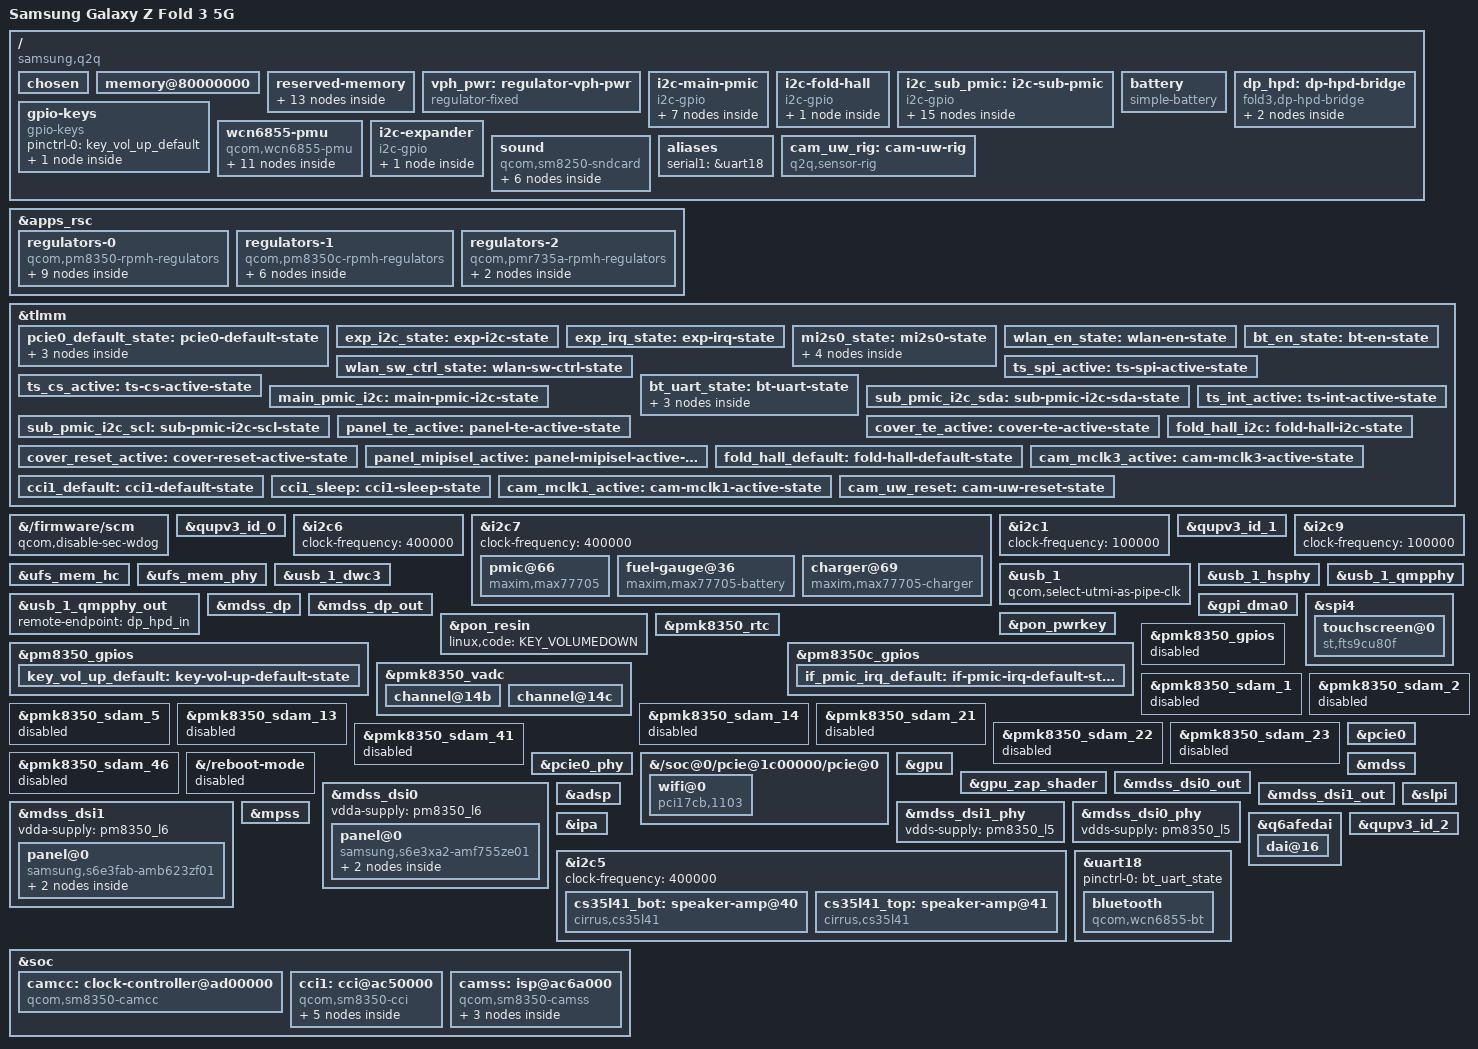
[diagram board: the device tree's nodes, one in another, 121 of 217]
// SPDX-License-Identifier: BSD-3-Clause
/*
 * Samsung Galaxy Z Fold 3 5G (SM-F926B, codename q2q)
 * SoC: Qualcomm SM8350 (lahaina)
 *
 * STAGE 1: deliberately minimal. Boots to an initramfs with a framebuffer
 * console and USB gadget, nothing else. UFS, DSI, Wi-Fi, audio and the
 * remoteprocs all come later -- the point of this file is the smallest thing
 * that can possibly boot, so that a failure has few candidate causes.
 *
 * Modelled on two upstream files:
 *   sm8350-sony-xperia-sagami.dtsi  -- correct SM8350 rails and PMIC labels
 *   sm8450-samsung-r0q.dts          -- Samsung conventions (splash_region, USB 2.0)
 *
 * Board data was read off the device on 2026-11-07, not guessed:
 *   /memory             the four ranges ABL itself publishes (11.90 GiB, 12 GB unit)
 *   reserved-memory     37 regions from the merged post-ABL DT
 *   framebuffer         cont_splash_region + the S6E3XA2 panel timings
 *   ro.revision = 9  ->  board DTS revision r08 is authoritative for this unit
 *
 * NOT BOOTED. NOT TESTED. See dts-work/README.md.
 */

/dts-v1/;

#include <dt-bindings/clock/qcom,sm8350-camcc.h>
#include <dt-bindings/gpio/gpio.h>
#include <dt-bindings/iio/qcom,spmi-adc7-pm8350.h>
#include <dt-bindings/interrupt-controller/arm-gic.h>
#include <dt-bindings/regulator/qcom,rpmh-regulator.h>
#include <dt-bindings/sound/qcom,q6afe.h>
#include <dt-bindings/sound/qcom,q6asm.h>

#include "sm8350.dtsi"
#include "pm8350.dtsi"
#include "pm8350c.dtsi"
#include "pmk8350.dtsi"

/ {
	model = "Samsung Galaxy Z Fold 3 5G";
	compatible = "samsung,q2q", "qcom,sm8350";
	chassis-type = "handset";

	/*
	 * ABL hands us no command line (uniLoader owns it, and the stock one is
	 * console=null anyway), so force our own in the kernel config with
	 * CONFIG_CMDLINE_FORCE.
	 */
	chosen {
		#address-cells = <2>;
		#size-cells = <2>;
		ranges;

		/*
		 * The bootloader framebuffer node is GONE as of the display stack
		 * landing. simpledrm owned it, and simpledrm cannot coexist with
		 * DPU: it would keep scanning out of XBL's surface while DPU
		 * reprograms the display controller under it. See the DISPLAY
		 * section at the end of this file.
		 *
		 * If you need the old console-on-the-bootloader-framebuffer path
		 * back -- e.g. to debug a panel that will not light -- flash
		 * golden/stage4-gpu-*, which still has it.
		 */
	};

	/*
	 * Explicit memory node. uniLoader carries this DT and ABL never rewrites
	 * it, so nothing will fill this in for us.
	 *
	 * These are the exact four ranges ABL publishes to the stock kernel,
	 * read out of the merged post-ABL DT:
	 *   0x080000000 + 0x37500000    893 MiB
	 *   0x0b7b00000 + 0x01e00000     30 MiB
	 *   0x0c0000000 + 0x140000000     5 GiB
	 *   0x200000000 + 0x180000000     6 GiB   = 11.90 GiB total
	 *
	 * Cross-checked: /proc/iomem on the stock kernel reports 11.41 GiB usable
	 * after carve-outs, which is consistent.
	 *
	 * (Worth noting: both the Galaxy S22 port and U-Boot's Qualcomm docs warn
	 * that Samsung bootloaders can emit a bogus or zero-sized memory node.
	 * On this device ABL's memory node is sane. Its *demura_region_0/1*
	 * reserved nodes ARE zero-sized, so the warning is not baseless -- it just
	 * does not apply to /memory here.)
	 */
	memory@80000000 {
		device_type = "memory";
		reg = <0x0 0x80000000 0x0 0x37500000>,
		      <0x0 0xb7b00000 0x0 0x01e00000>,
		      <0x0 0xc0000000 0x1 0x40000000>,
		      <0x2 0x00000000 0x1 0x80000000>;
	};

	reserved-memory {
		/*
		 * Samsung-specific carve-outs that sm8350.dtsi does not know about.
		 * The generic Qualcomm regions (hyp, xbl_aop, smem, cpucp_fw,
		 * cdsp_secure_heap, pil_*, rmtfs, removed, qrtr_shbuf, chan*_shbuf)
		 * are inherited from sm8350.dtsi unchanged -- verified to match
		 * lahaina.dtsi's own values, so upstream is already correct for this
		 * device and must NOT be overridden.
		 */

		/*
		 * Naming here is genuinely ambiguous and worth knowing about.
		 *
		 * Upstream sm8450-samsung-r0q.dts carries the comment "the bootloader
		 * will only keep display hardware enabled if this memory region is
		 * named exactly 'splash_region'" -- and then writes the node as
		 * "splash-region@b8000000", with a hyphen. It contradicts itself.
		 * Samsung's own DT on this device uses "splash_region" (underscore, no
		 * unit address) plus label = "cont_splash_region".
		 *
		 * For OUR boot path it does not matter: uniLoader presents itself to
		 * ABL as a kernel, so ABL never parses this DT at all. The only job
		 * this node has is stopping Linux from allocating over the framebuffer.
		 * We keep the underscore (matching both the stated requirement and
		 * Samsung) and add a unit address so dtc stays quiet.
		 *
		 * If we ever boot WITHOUT uniLoader -- e.g. the Galaxy M52 approach of
		 * injecting a DT into vendor_boot, where ABL does read it -- and the
		 * display dies, try renaming this to bare "splash_region" first.
		 */
		/*
		 * ADSP. NOT inherited from sm8350.dtsi -- the header comment's
		 * "pil_* verified to match" was wrong for this one. The merged
		 * post-ABL DT puts the PIL regions here:
		 *     pil_adsp    0x85200000 + 0x3000000   (upstream: 0x86100000 + 0x2100000)
		 *     pil_camera  0x9b800000, pil_video 0x9bd00000,
		 *     pil_cvp     0x9c200000, pil_slpi  0x9c700000
		 * i.e. Samsung grew the ADSP down over upstream's camera/video/cvp
		 * slots and moved those above the modem. The three upstream slots
		 * are deleted and the ADSP gets the vendor's 48 MiB. Net reserved
		 * memory is unchanged (0x85200000-0x88200000 was all no-map before).
		 *
		 * camera/video/cvp/slpi are NOT re-declared at Samsung's addresses:
		 * nothing loads them, and 0x9bb00000 is where uniLoader relocates
		 * the kernel payloads. Upstream's pil_slpi_mem (0x88200000) stays,
		 * unused.
		 */
		/delete-node/ memory@85200000;
		/delete-node/ memory@85700000;
		/delete-node/ memory@85c00000;
		/delete-node/ memory@86100000;

		pil_adsp_mem: memory@85200000 {
			reg = <0x0 0x85200000 0x0 0x3000000>;
			no-map;
		};

		/*
		 * SLPI (sensor hub: the LSM6DSO IMU and friends live behind it).
		 * slpi.mdt is linked at 0x88200000 and spans exactly 0x1600000
		 * (22 MiB, measured from its program headers). Upstream's slot
		 * at 0x88200000 is 0x1500000 and abuts pil_cdsp at 0x89700000,
		 * so the image cannot fit there -- which is why Samsung moved it.
		 * Use Samsung's own slot from the merged post-ABL DT.
		 *
		 * CONSTRAINT: ABL loads the uniLoader blob at 0x9bb00000 and the
		 * FDT the kernel keeps using stays inside it, just after the
		 * Image (0x9ec9d000 with a 47.5 MiB Image). This no-map region
		 * ends at 0x9dd00000. If the Image ever shrinks below ~34 MiB
		 * the FDT lands inside it and the boot dies very early.
		 */
		/delete-node/ memory@88200000;

		pil_slpi_mem: memory@9c700000 {
			reg = <0x0 0x9c700000 0x0 0x1600000>;
			no-map;
		};

		splash_region: splash_region@e4000000 {
			reg = <0x0 0xe4000000 0x0 0x2300000>;
			label = "cont_splash_region";
			no-map;
		};

		dfps_data_region@e6300000 {
			reg = <0x0 0xe6300000 0x0 0x100000>;
			no-map;
		};

		/*
		 * Samsung TrustZone / "Universal Hypervisor" (RKP). Installed by the
		 * bootloader before any kernel runs, so this memory is occupied no
		 * matter whose kernel boots. Touching it faults.
		 */
		tima_region@b0100000 {
			reg = <0x0 0xb0100000 0x0 0x100000>;
			no-map;
		};

		uh_heap_region@b0200000 {
			reg = <0x0 0xb0200000 0x0 0x200000>;
			no-map;
		};

		uh_guest_region@b0400000 {
			reg = <0x0 0xb0400000 0x0 0x1800000>;
			no-map;
		};

		hdm_region@9fb00000 {
			reg = <0x0 0x9fb00000 0x0 0x1000>;
			no-map;
		};

		/* Where ABL leaves the KASLR seed. */
		kaslr_region@a0001000 {
			reg = <0x0 0xa0001000 0x0 0x1000>;
			no-map;
		};

		/* Samsung debug areas. Reserved so the kernel does not reuse them. */
		sec_debug_region@f0000000 {
			reg = <0x0 0xf0000000 0x0 0x900000>;
			no-map;
		};

		ss_plog_region@f0900000 {
			reg = <0x0 0xf0900000 0x0 0x200000>;
			no-map;
		};

		sec_debug_rdx_bootdev@100000000 {
			reg = <0x1 0x00000000 0x0 0xad00000>;
			no-map;
		};

		/*
		 * ramoops. With no UART, this is the only way to read a panic from
		 * the *previous* boot, so it is worth having from day one.
		 * Deliberately NOT no-map: pstore has to be able to map it.
		 */
		ramoops_region: ramoops@f0b00000 {
			compatible = "ramoops";
			reg = <0x0 0xf0b00000 0x0 0x100000>;
			/*
			 * Mirrors Samsung's own ramoops node byte for byte: four
			 * 256 KiB zones filling the 1 MiB region, and NO ecc-size.
			 *
			 * The first version of this node asked for 512/256/128/128
			 * plus ecc-size = 16. The zones alone already filled the
			 * region exactly, so the ECC data had nowhere to live and the
			 * driver did not probe -- /sys/fs/pstore came back empty after
			 * a run we KNOW executed. Without a UART this is our only
			 * black box, so it has to actually work.
			 */
			console-size = <0x40000>;
			record-size  = <0x40000>;
			pmsg-size    = <0x40000>;
			ftrace-size  = <0x40000>;
		};
	};

	vph_pwr: regulator-vph-pwr {
		compatible = "regulator-fixed";
		regulator-name = "vph_pwr";
		regulator-min-microvolt = <3700000>;
		regulator-max-microvolt = <3700000>;
		regulator-always-on;
		regulator-boot-on;
	};
};

/*
 * Regulators. Minimal on purpose: only the rails the USB HS PHY needs, plus
 * their parents. Voltages are taken verbatim from upstream
 * sm8350-sony-xperia-sagami.dtsi -- these are PMIC-level constraints on the
 * same PMICs at the same rails, so they transfer.
 */
&apps_rsc {
	regulators-0 {
		compatible = "qcom,pm8350-rpmh-regulators";
		qcom,pmic-id = "b";

		vdd-s1-supply = <&vph_pwr>;
		vdd-s2-supply = <&vph_pwr>;
		vdd-s3-supply = <&vph_pwr>;
		vdd-s4-supply = <&vph_pwr>;
		vdd-s5-supply = <&vph_pwr>;
		vdd-s6-supply = <&vph_pwr>;
		vdd-s7-supply = <&vph_pwr>;
		vdd-s8-supply = <&vph_pwr>;
		vdd-s9-supply = <&vph_pwr>;
		vdd-s10-supply = <&vph_pwr>;
		vdd-s11-supply = <&vph_pwr>;
		vdd-s12-supply = <&vph_pwr>;

		vdd-l1-l4-supply = <&pm8350_s11>;
		vdd-l2-l7-supply = <&vreg_bob>;
		vdd-l3-l5-supply = <&vreg_bob>;
		vdd-l6-l9-l10-supply = <&pm8350_s11>;

		/*
		 * ARC regulators (not described here):
		 *   S5 - mx.lvl   S6 - gfx.lvl   S9 - mxc.lvl
		 */

		/* vdd-wlan-io on the vendor's QCA6490: 1.8V, S10B */
		pm8350_s10: smps10 {
			regulator-name = "pm8350_s10";
			regulator-min-microvolt = <1800000>;
			regulator-max-microvolt = <1800000>;
			regulator-initial-mode = <RPMH_REGULATOR_MODE_HPM>;
		};

		pm8350_s11: smps11 {
			regulator-name = "pm8350_s11";
			regulator-min-microvolt = <752000>;
			regulator-max-microvolt = <1000000>;
			regulator-initial-mode = <RPMH_REGULATOR_MODE_HPM>;
		};

		pm8350_s12: smps12 {
			regulator-name = "pm8350_s12";
			regulator-min-microvolt = <1224000>;
			regulator-max-microvolt = <1360000>;
			regulator-initial-mode = <RPMH_REGULATOR_MODE_HPM>;
		};

		/*
		 * USB3+DP combo PHY vdda-phy (2026-11-19). 912 mV, which is not a
		 * guess from either direction: the vendor DT's ssphy@88e8000 has
		 *   vdd-supply = <&pm8350_l1>  (phandle 0xf2 -> rpmh-regulator-ldob1)
		 *   qcom,vdd-voltage-level = <0 0xdea80 0xdea80>   = 912000 uV
		 * and sm8350-hdk independently sets vreg_l1b_0p88 to 912-920 mV for
		 * the same rail. On the 8 mV pmic5 LDO grid, so it cannot be the
		 * off-grid-voltage failure that takes the whole PMIC probe down.
		 */
		pm8350_l1: ldo1 {
			regulator-name = "pm8350_l1";
			regulator-min-microvolt = <912000>;
			regulator-max-microvolt = <912000>;
			regulator-initial-mode = <RPMH_REGULATOR_MODE_HPM>;
		};

		/* USB HS PHY vdda33 */
		pm8350_l2: ldo2 {
			regulator-name = "pm8350_l2";
			regulator-min-microvolt = <3072000>;
			regulator-max-microvolt = <3072000>;
			regulator-initial-mode = <RPMH_REGULATOR_MODE_HPM>;
		};

		/* USB HS PHY vdda-pll */
		/* UFS PHY PLL. Rail assignment matches sm8350-hdk/mtp/surface-duo2. */
		pm8350_l6: ldo6 {
			regulator-name = "vreg_l6b_1p2";
			regulator-min-microvolt = <1200000>;
			regulator-max-microvolt = <1200000>;
			regulator-initial-mode = <RPMH_REGULATOR_MODE_HPM>;
		};

		/* UFS vcc, the device's main 2.96 V rail. */
		pm8350_l7: ldo7 {
			regulator-name = "vreg_l7b_2p96";
			regulator-min-microvolt = <2960000>;
			regulator-max-microvolt = <2960000>;
			regulator-initial-mode = <RPMH_REGULATOR_MODE_HPM>;
		};

		/* UFS vccq + vdd-hba. */
		pm8350_l9: ldo9 {
			regulator-name = "vreg_l9b_1p2";
			regulator-min-microvolt = <1200000>;
			regulator-max-microvolt = <1200000>;
			regulator-initial-mode = <RPMH_REGULATOR_MODE_HPM>;
		};

		pm8350_l5: ldo5 {
			regulator-name = "pm8350_l5";
			regulator-min-microvolt = <880000>;
			regulator-max-microvolt = <888000>;
			regulator-initial-mode = <RPMH_REGULATOR_MODE_HPM>;
			regulator-allow-set-load;
			regulator-allowed-modes = <RPMH_REGULATOR_MODE_LPM
						   RPMH_REGULATOR_MODE_HPM>;
		};
	};

	regulators-1 {
		compatible = "qcom,pm8350c-rpmh-regulators";
		qcom,pmic-id = "c";

		vdd-s1-supply = <&vph_pwr>;
		vdd-s2-supply = <&vph_pwr>;
		vdd-s3-supply = <&vph_pwr>;
		vdd-s4-supply = <&vph_pwr>;
		vdd-s5-supply = <&vph_pwr>;
		vdd-s6-supply = <&vph_pwr>;
		vdd-s7-supply = <&vph_pwr>;
		vdd-s8-supply = <&vph_pwr>;
		vdd-s9-supply = <&vph_pwr>;
		vdd-s10-supply = <&vph_pwr>;

		vdd-l1-l12-supply = <&pm8350c_s1>;
		vdd-l2-l8-supply = <&pm8350c_s1>;
		vdd-l3-l4-l5-l7-l13-supply = <&vreg_bob>;
		vdd-l6-l9-l11-supply = <&vreg_bob>;
		vdd-l10-supply = <&pm8350_s12>;
		vdd-bob-supply = <&vph_pwr>;

		pm8350c_s1: smps1 {
			/*
			 * PINNED to 1.984 V. Generic lahaina-regulators.dtsi
			 * has 1.8-1.952 V (init 1.88), but the q2q overlay
			 * replaces the whole node with min = max = init =
			 * 1984000 (fragment@199, regulator-pm8350c-s1), and
			 * that is what vdd-wlan-rfa1 is configured to. With a
			 * range, RPMh left it at 1.808 V -- 176 mV under what
			 * Samsung runs the QCA6490's 1.9 V RF rail at.
			 * Since the vendor pins it board-wide, every other
			 * consumer (the L1/L2/L8/L12 parents) already lives
			 * with this value on stock.
			 */
			regulator-name = "pm8350c_s1";
			regulator-min-microvolt = <1984000>;
			regulator-max-microvolt = <1984000>;
			regulator-initial-mode = <RPMH_REGULATOR_MODE_HPM>;
		};

		vreg_bob: bob {
			regulator-name = "vreg_bob";
			regulator-min-microvolt = <3400000>;
			regulator-max-microvolt = <3960000>;
			regulator-initial-mode = <RPMH_REGULATOR_MODE_AUTO>;
		};

		/* USB HS PHY vdda18 */
		pm8350c_l1: ldo1 {
			regulator-name = "pm8350c_l1";
			regulator-min-microvolt = <1800000>;
			regulator-max-microvolt = <1800000>;
			regulator-initial-mode = <RPMH_REGULATOR_MODE_HPM>;
		};

		/*
		 * SENSOR RAILS. XBL leaves all three OFF (read back over SPMI:
		 * EN_CTL 0x00 at 0xc246 / 0xc946 / 0xcc46 -- note the LDO
		 * peripherals start at 0xc100, so LDOn is at 0xc000 + n*0x100).
		 * Android's kernel is what turns them on:
		 *   L2C  1.8 V  "sensor_vdd" -- held by the vendor PIL node
		 *        (qcom,ssc@5c00000, qcom,active-reg-names) for as long
		 *        as the SLPI runs
		 *   L9C  2.9 V  regulator-always-on, no named consumer
		 *   L12C 1.8 V  regulator-always-on, no named consumer
		 * With them off the I3C IMU still answers but EVERY I2C sensor
		 * (ak0991x, ak0997x, lps22hh, stk3a9x, tcs3407 -- SSC buses
		 * 3/4/5/7) hangs its driver until the SLPI watchdog kills the
		 * sensor PD: "SNS_SEE_P_x exceeded processing time limit".
		 * Found by bisecting the registry, one driver at a time.
		 * mainline's qcom_q6v5_pas has no supply for this, hence
		 * always-on rather than a consumer.
		 *
		 * State of knowledge, 2026-11-12:
		 *   L2C  on  -> mag, baro, hall, light all work via libssc
		 *   L12C on  -> boots fine, changes nothing visible
		 *   L9C on  -> boots fine at an ON-GRID voltage; see below
		 * Still broken with L2C+L12C (and main-S2MPB02 LDO8 + sub LDO12
		 * poked on by hand): the stk3a9x proximity driver hangs the
		 * SLPI, and the LSM6DSO IMU never enumerates.
		 */
		pm8350c_l2: ldo2 {
			regulator-name = "pm8350c_l2";
			regulator-min-microvolt = <1800000>;
			regulator-max-microvolt = <1800000>;
			regulator-initial-mode = <RPMH_REGULATOR_MODE_HPM>;
			regulator-always-on;
		};

		/*
		 * L9C. Vendor: fixed 2.9 V, regulator-always-on (overlay
		 * fragment@196); almost certainly the main SX9360 grip sensor's
		 * supply. Declared at 2.904 V (boots fine, verified), because
		 * mainline's pmic5_pldo only has an 8 mV grid from 1.504 V and
		 * 2.900 V is NOT on it. With min = max = 2.9 V the core cannot
		 * apply the constraint, rpmh_regulator_probe() fails for the
		 * WHOLE PMIC, and pm8350c_l1 (USB PHY), pm8350c_s1 and vreg_bob
		 * (UFS VCC's parent) go with it -- which is what the two "L9C
		 * kills the phone" boots most likely were: no USB, no rootfs,
		 * black screen. Not a power cut. The PMIC's own VSET reads
		 * 2.960 V with this vote in place (XBL's preset, and the
		 * reference boards' value), so something else votes higher.
		 * RULE: every RPMh LDO voltage must satisfy
		 * (uV - range_min) % step == 0 for its type in
		 * drivers/regulator/qcom-rpmh-regulator.c.
		 */
		pm8350c_l9: ldo9 {
			regulator-name = "pm8350c_l9";
			regulator-min-microvolt = <2904000>;
			regulator-max-microvolt = <2904000>;
			regulator-initial-mode = <RPMH_REGULATOR_MODE_HPM>;
			regulator-always-on;
		};

		/* L12C: boots fine alone; did not bring the IMU up */
		pm8350c_l12: ldo12 {
			regulator-name = "pm8350c_l12";
			regulator-min-microvolt = <1800000>;
			regulator-max-microvolt = <1800000>;
			regulator-initial-mode = <RPMH_REGULATOR_MODE_HPM>;
			regulator-always-on;
		};
	};
	/*
	 * PMR735A, RPMh id "e". Added for Wi-Fi: the QCA6490's VDD_PMU_MX
	 * comes from S2E, and the antenna switch from L7E. These are RPMh
	 * rails, so no pmr735a.dtsi include is needed -- only this block.
	 * Constraints taken from sm8350-hdk / sagami, same PMIC, same rails.
	 */
	regulators-2 {
		compatible = "qcom,pmr735a-rpmh-regulators";
		qcom,pmic-id = "e";

		vdd-s1-supply = <&vph_pwr>;
		vdd-s2-supply = <&vph_pwr>;
		vdd-s3-supply = <&vph_pwr>;
		vdd-l7-bob-supply = <&vreg_bob>;

		pmr735a_s2: smps2 {
			/*
			 * VDD_PMU_MX for the QCA6490, and the vendor's
			 * vdd-wlan-aon. PINNED, not a range, and that is the
			 * point: pwrseq-qcom-wcn only ever calls
			 * regulator_bulk_enable() -- it never requests a
			 * voltage -- and the regulator core applies a DT
			 * voltage only when min == max. With a range, this
			 * rail comes up enabled at whatever RPMh happens to
			 * have aggregated, which for a rail no bootloader
			 * touches is not 1.012 V.
			 *
			 * 1012000 is the vendor's own value, exactly:
			 *   lahaina.dtsi qcom,cnss-qca6490@b0000000
			 *   vdd-wlan-aon-supply = <&S2E>
			 *   qcom,vdd-wlan-aon-config = <1012000 1012000 0 0 1>
			 * and it is inside the hardware's range -- vendor
			 * lahaina-regulators.dtsi constrains S2E to
			 * 500000-1020000 with init 852000.
			 *
			 * The old 950000-976000 was copied from
			 * sm8350-sony-xperia-sagami, where S2E serves
			 * something else entirely. It cannot even reach
			 * 1.012 V, so this rail was capped ~36 mV low.
			 *
			 * Safe to pin: &pmr735a_s2 has exactly ONE consumer
			 * in this file, the wcn6855-pmu's vddpmumx. Compare
			 * S11B/S1C/S12B, which the vendor also drives for
			 * WLAN but which are shared with the UFS LDO parents
			 * and the display vddio here -- deliberately NOT
			 * touched. Note S10B is already pinned 1.8/1.8 and is
			 * the one WLAN rail previously reported healthy.
			 */
			regulator-name = "pmr735a_s2";
			regulator-min-microvolt = <1012000>;
			regulator-max-microvolt = <1012000>;
		};

		/*
		 * wlan-ant-switch on the vendor DT (L7E, 2.8V). The upstream
		 * wcn6855-pmu binding has no supply for it, so nothing would
		 * ever turn it on -- and with the antenna switch unpowered the
		 * radio may associate at no useful range. always-on is the
		 * cheap, harmless way to guarantee it: if it turns out not to
		 * be the ant switch, an always-on 2.8V LDO costs us nothing.
		 */
		pmr735a_l7: ldo7 {
			regulator-name = "pmr735a_l7";
			regulator-min-microvolt = <2800000>;
			regulator-max-microvolt = <2800000>;
			regulator-always-on;
		};
	};

};

/*
 * TLMM: reserve EVERY gpio.
 *
 * sm8350-tlmm probe is where boot hangs. dyndbg caught it exactly:
 *   platform f100000.pinctrl: really_probe: probing driver sm8350-tlmm
 *   <no driver_bound, no "probe of ... returned" -- it never comes back>
 *
 * gpiochip_add_data() calls ->get_direction() per line, but only where
 * gpiochip_line_is_valid() (gpiolib.c:1316). On Samsung devices the secure
 * world owns some TLMM lines and reading their config register hangs the
 * bus. gpio-reserved-ranges clears those bits so the read never happens.
 *
 * Every other SM8350 board upstream sets this and ours did not:
 *   sm8350-hdk / sm8350-mtp      <52 8>
 *   sony-xperia-sagami           <44 4>
 *   microsoft-surface-duo2       <4 4>, <12 4>, <56 4>, <76 4>
 *
 * The real q2q set is unknown, and the values above disagree, so this is
 * deliberately ALL 204 lines: Stage 1 needs no GPIO whatsoever, and a total
 * reserve turns "which lines are protected?" into a yes/no question. Once
 * boot gets past tlmm, bisect this down to the true set.
 */
&tlmm {
	/*
	 * 203 of 204 lines stay reserved. GPIO 203 is the UFS reset, and every
	 * upstream SM8350 board that has working UFS drives it:
	 *   sm8350-hdk / mtp / surface-duo2:  reset-gpios = <&tlmm 203 ...>
	 * Freeing one line at a time keeps the blanket reserve honest until the
	 * genuinely TZ-owned set is known.
	 *
	 * Freed so far, each for a named reason:
	 *     5        nothing of ours. Freed on the belief that it carried the
	 *              max77705 interrupt; it does not. The vendor DT has
	 *              max77705,irq-gpio = <&pm8350c_gpios 5 GPIO_ACTIVE_LOW>,
	 *              i.e. the INTB line is a PM8350C GPIO behind SPMI, not a
	 *              TLMM line (2026-11-14, confirmed by resolving the phandle
	 *              in q2q_eur_openx_w00_r03.dts to qcom,pm8350c-gpio). Left
	 *              freed rather than re-reserved in the same flash as the
	 *              charger work: nothing requests it, so it is inert.
	 *     32, 33   qup7 i2c SDA/SCL -- the bus the max77705 sits on.
	 *              Without these, geni_i2c probes but pinctrl fails:
	 *                sm8350-tlmm: error -EINVAL: pin-32 (99c000.i2c)
	 *                geni_i2c 99c000.i2c: Error applying setting
	 *     203      UFS reset
	 *     20-23    QUP0 SE4 SPI -- the inner panel's touch controller
	 *              (20 MISO, 21 MOSI, 22 CLK, 23 CS)
	 *     165      touch IRQ
	 *
	 * 20-23 and 165 are provably NOT TZ-owned: the stock NON-SECURE kernel
	 * muxes and drives all five for exactly this purpose -- see
	 * capture/facts-<stamp>/dt/q2q-merged-postabl.dts, nodes
	 * spi_{mosi,miso,clk}_tsp_active and tsp_int_active.
	 *
	 * Everything else stays reserved until the real TZ-owned set is known.
	 */
	/*
	 * Freed for audio (2026-11-12), all plain non-secure TLMM pins in the
	 * vendor DT: 25 (i2c5 SCL, with 24), 51 (expander irq), 125-128
	 * (MI2S0 sck/data0/data1/ws), 171/172 (expander i2c-gpio).
	 */
	/*
	 * Freed for the fold switch (2026-11-13): 80 (INT of the AK09970
	 * digital hall, vendor folder_hall_irq) and 104/105 (its i2c-gpio
	 * bus, vendor dhall_i2c_active). Plain non-secure pins, all three
	 * driven through /dev/mem without a fault first. 81 stays reserved.
	 */
	/*
	 * Freed for the battery limiters (2026-11-12): 8/9 (qup1 i2c, main
	 * s2asl01 @0x38) and 40/41 (qup9 i2c, sub s2asl01 @0x39). Plain
	 * non-secure pins in the vendor DT (qupv3_se1/se9_i2c_active), and the
	 * bootloader already leaves all four muxed to QUP with pull-ups.
	 */
	/*
	 * Freed for the camera MCLK (2026-11-14): 103, CAMIF_MCLK3, the master
	 * clock the cover camera module (cam-sensor11/13, IMX374) needs at
	 * 24 MHz before its i2c slave answers. <98 6> covered 98-103 and
	 * becomes <98 5>. Plain non-secure pin: the vendor's
	 * cam_sensor_mclk3_active muxes it to function "cam_mclk" from the
	 * non-secure world, and mainline's pinctrl-sm8350 agrees that
	 * cam_mclk is gpio103's function 1.
	 */
	/*
	 * Freed for the camera EEPROM probe (2026-11-14): 28/29, the qup6 i2c
	 * bus that carries the rear module's calibration EEPROM
	 * (qcom,eeprom11, slave 0xa2 = 7-bit 0x51). Plain non-secure pins --
	 * the vendor's qupv3_se6_i2c_active muxes both to function "qup6" with
	 * bias-pull-up and drive-strength 2, which is byte-for-byte what
	 * upstream's own qup_i2c6_default state already says, so no new
	 * pinctrl state is needed here.
	 *
	 * <26 6> covered 26-31; it becomes <26 2>, <30 2> so only 28/29 open.
	 */
	/*
	 * Freed for the rear ultrawide camera (2026-11-15): 101, 106 and
	 * 111-114. All five are plain non-secure pins that the vendor kernel
	 * muxes from the non-secure world, exactly as argued for 103 above:
	 *
	 *   101       CAMIF_MCLK1, the IMX258's 19.2 MHz master clock
	 *             (vendor cam_sensor_mclk1_active, function "cam_mclk";
	 *             mainline pinctrl-sm8350 agrees cam_mclk is func 1 here).
	 *   106       UWCAM_RST_N, the module's reset (vendor
	 *             cam_sensor_active_rst2, function "gpio").
	 *   111/112   CCI_I2C_DATA2/CLK2 -- hardware CCI1 master 0, the bus the
	 *             IMX258 and its cal EEPROM sit on (vendor cci2_active).
	 *   113/114   CCI_I2C_DATA3/CLK3 -- CCI1 master 1 (vendor cci3_active).
	 *             Declared with the bus but carries nothing we drive yet.
	 *
	 * <98 5> covered 98-102 and becomes <98 3>, <102 1> so only 101 opens.
	 * <106 19> covered 106-124 and becomes <107 4>, <115 10>, which opens
	 * 106 and 111-114 while leaving 107-110 (CCI0's two masters, for the
	 * wide and front cameras) still reserved.
	 */
	gpio-reserved-ranges = <0 5>, <6 2>, <10 5>, <18 2>, <26 2>, <30 2>, <34 6>,
			       <42 9>, <52 12>,
			       <66 2>, <72 4>, <81 1>, <84 10>, <98 3>, <102 1>,
			       <107 4>, <115 10>, <129 24>,
			       <154 11>, <166 5>, <173 30>;

	/*
	 * Freed for the inner display, all three taken from the vendor DT
	 * (lahaina-pinctrl.dtsi + q2q_eur_openx_w00_r08.dts), where they are
	 * plain TLMM pins muxed from the non-secure world:
	 *   24  panel reset     (sde_dsi_active, was inside <24 8>)
	 *   82  panel TE/vsync  (sde_te_active,  was inside <78 16>)
	 *   97  mipi-sel        (panel_xa2_ze01_mipisel_active, was <97 56>)
	 * Note the reset pin is 24 (vendor qcom,platform-reset-gpio = 0x18).
	 * An earlier sketch in panel-work/display.dtsi said 14; that was wrong.
	 */

	/*
	 * Freed for DisplayPort over USB-C (2026-11-19): 15 and 16, the AUX/SBU
	 * analog switch, so <10 7> became <10 5>. Both are plain TLMM pins muxed
	 * to the "gpio" function from the non-secure world in the vendor DT --
	 * q2q_eur_openx_w00_r08.dts fragment@239:
	 *   15  sde_dp_aux_sel_{active,suspend}   AUX polarity select
	 *   16  sde_dp_aux_en_{active,suspend}    switch enable
	 * The suspend state of 16 is output-HIGH and of 15 output-low, so the
	 * enable is ACTIVE LOW -- which is how the gpio-sbu-mux node below
	 * declares it. This is the same reasoning that freed 24/82/97 above: the
	 * stock non-secure kernel drives them for exactly this purpose, so they
	 * are provably not TZ-owned.
	 */

	/*
	 * 94/95/96 (PCIe perst, clkreq, wake) are free and PROVEN SAFE:
	 * booted with them carved out on 2026-11-11. An earlier boot with
	 * this exact DTB looked like a TZ hang and was not -- the device
	 * simply needs the USB cable replugged during first stage before it
	 * continues, and until then the console backpressure makes it look
	 * dead. Do not re-reserve these on that evidence.
	 */

	/*
	 * <34 42> + <78 87> is the old <34 131> with 76 and 77 carved out:
	 * they are the bitbanged i2c to the s2dos05 display PMIC, which owns
	 * the two touch rails. Vendor pin states gpio_i2c_2_sda/scl_default
	 * mux both to "gpio", so they are TLMM-owned in the vendor DT too --
	 * but whether TZ also claims them is only provable by booting.
	 */

	/*
	 * Inner-display touch (ST FTS9CU80F) on QUP0 SE4.
	 *
	 * CS is a plain GPIO, not qup4's native chip select, mirroring the stock
	 * driver: it holds CS low across an entire spi_message, including the
	 * inter-transfer delay a register read needs. cs-gpios gets us the same
	 * behaviour from the SPI core.
	 */
	/*
	 * QCA6490 enable lines. Vendor cnss_wlan_en_active: gpio function,
	 * drive-strength 16, bias-pull-up, output-high. sw-ctrl is an input
	 * back from the chip's PMU, so it gets a pull-down and no drive.
	 */
	/*
	 * PCIe0 control pins. Without perst the endpoint is never released
	 * from reset. gpio95 is NOT a plain GPIO -- clkreq has its own TLMM
	 * function, pcie0_clkreqn. Pin numbers are the vendor's (perst-gpio
	 * 0x5e = 94, wake-gpio 0x60 = 96), matching sm8350-hdk.
	 */
	pcie0_default_state: pcie0-default-state {
		perst-pins {
			pins = "gpio94";
			function = "gpio";
			drive-strength = <2>;
			bias-pull-down;
		};

		clkreq-pins {
			pins = "gpio95";
			function = "pcie0_clkreqn";
			drive-strength = <2>;
			bias-pull-up;
		};

		wake-pins {
			pins = "gpio96";
			function = "gpio";
			drive-strength = <2>;
			bias-pull-up;
		};
	};

	/* Bitbanged i2c to the PCAL6524 GPIO expander (vendor /i2c@53). */
	exp_i2c_state: exp-i2c-state {
		pins = "gpio171", "gpio172";
		function = "gpio";
		drive-strength = <2>;
		bias-disable;
		input-enable;
	};

	exp_irq_state: exp-irq-state {
		pins = "gpio51";
		function = "gpio";
		drive-strength = <2>;
		bias-pull-up;
	};

	/*
	 * MI2S0, the speaker amps' audio bus. Vendor names these pri_tdm_*;
	 * same four pins, same TLMM functions, whichever framing the DSP uses.
	 * data1 is SoC -> amps, data0 is the amps' feedback path.
	 */
	mi2s0_state: mi2s0-state {
		sck-pins {
			pins = "gpio125";
			function = "mi2s0_sck";
			drive-strength = <2>;
			bias-disable;
		};

		ws-pins {
			pins = "gpio128";
			function = "mi2s0_ws";
			drive-strength = <2>;
			bias-disable;
		};

		data0-pins {
			pins = "gpio126";
			function = "mi2s0_data0";
			drive-strength = <2>;
			bias-disable;
		};

		data1-pins {
			pins = "gpio127";
			function = "mi2s0_data1";
			drive-strength = <2>;
			bias-disable;
		};
	};

	wlan_en_state: wlan-en-state {
		pins = "gpio64";
		function = "gpio";
		drive-strength = <16>;
		bias-pull-up;
	};

	bt_en_state: bt-en-state {
		pins = "gpio65";
		function = "gpio";
		drive-strength = <16>;
		bias-pull-up;
	};

	wlan_sw_ctrl_state: wlan-sw-ctrl-state {
		pins = "gpio153";
		function = "gpio";
		bias-pull-down;
		input-enable;
	};

	ts_spi_active: ts-spi-active-state {
		pins = "gpio20", "gpio21", "gpio22";
		function = "qup4";
		drive-strength = <6>;
		bias-disable;
	};

	ts_cs_active: ts-cs-active-state {
		pins = "gpio23";
		function = "gpio";
		drive-strength = <6>;
		bias-disable;
		output-high;
	};

	/*
	 * Bitbanged i2c to the s2dos05. Vendor: gpio_i2c_2_sda_default /
	 * gpio_i2c_2_scl_default -- gpio function, drive-strength 2,
	 * bias-disable, input-enable. No internal pull: the board has
	 * external pull-ups, which open-drain bitbanging requires.
	 */
	/*
	 * Bluetooth UART = QUP18 (vendor qupv3_se18_4uart @ 0x890000), 4-wire.
	 * GENI lane order: 68 CTS, 69 RTS, 70 TX, 71 RX. sm8350.dtsi's own
	 * qup_uart18_default only lists 68/69, which cannot be a working
	 * 2-wire UART on these lanes, so it is replaced rather than extended.
	 * 68-71 came out of gpio-reserved-ranges for this; the stock kernel
	 * muxes all four to qup18 from the non-secure world.
	 */
	bt_uart_state: bt-uart-state {
		cts-pins {
			pins = "gpio68";
			function = "qup18";
			bias-bus-hold;
		};

		rts-tx-pins {
			pins = "gpio69", "gpio70";
			function = "qup18";
			drive-strength = <2>;
			bias-disable;
		};

		rx-pins {
			pins = "gpio71";
			function = "qup18";
			bias-pull-up;
		};
	};

	/* main S2MPB02 bus, vendor /i2c@51: plain HLOS gpios, bias-disable */
	main_pmic_i2c: main-pmic-i2c-state {
		pins = "gpio78", "gpio79";
		function = "gpio";
		drive-strength = <2>;
		bias-disable;
	};

	sub_pmic_i2c_sda: sub-pmic-i2c-sda-state {
		pins = "gpio76";
		function = "gpio";
		drive-strength = <2>;
		bias-disable;
		input-enable;
	};

	sub_pmic_i2c_scl: sub-pmic-i2c-scl-state {
		pins = "gpio77";
		function = "gpio";
		drive-strength = <2>;
		bias-disable;
		input-enable;
	};

	ts_int_active: ts-int-active-state {
		pins = "gpio165";
		function = "gpio";
		drive-strength = <2>;
		bias-disable;
		input-enable;
	};

	/*
	 * Inner display. Vendor states sde_dsi_active (reset) and
	 * sde_te_active (TE) in lahaina-pinctrl.dtsi, and
	 * panel_xa2_ze01_mipisel_active in the board DTS.
	 *
	 * TE is NOT a gpio consumer: it is muxed to the mdp_vsync function so
	 * the panel's tear-effect line reaches the DPU's INTF directly in
	 * hardware. A command-mode panel has no periodic timing of its own --
	 * the host pushes a frame when TE says the scanout has wrapped -- so
	 * without this mux there is no vsync at all.
	 */
	panel_te_active: panel-te-active-state {
		pins = "gpio82";
		function = "mdp_vsync";
		drive-strength = <2>;
		bias-pull-down;
	};

	/*
	 * Cover panel (S6E3FAB). TE is TLMM 83 = the SECONDARY mdp_vsync input
	 * (vendor qcom,panel-te-source = <1>); reset is TLMM 17 (Samsung node:
	 * qcom,platform-reset-gpio = <&tlmm 0x11 0>). Both freed from
	 * gpio-reserved-ranges for this.
	 */
	cover_te_active: cover-te-active-state {
		pins = "gpio83";
		function = "mdp_vsync";
		drive-strength = <2>;
		bias-pull-down;
	};

	cover_reset_active: cover-reset-active-state {
		pins = "gpio17";
		function = "gpio";
		drive-strength = <8>;
		bias-disable;
	};

	panel_mipisel_active: panel-mipisel-active-state {
		pins = "gpio97";
		function = "gpio";
		drive-strength = <2>;
		bias-disable;
	};
};

/*
 * Battery profile. This is the only thing the mainline max77705 charger reads
 * from DT, and voltage-max-design-microvolt is load-bearing:
 * max77705_charger_initialize() feeds it straight into
 * max77705_set_float_voltage() at every probe, so this number IS the voltage
 * the pack is charged to.
 *
 * Samsung's own q2q values, for reference:
 *     battery,chg_float_voltage   = 4380 mV  (0x111c, r03)
 *     battery,max_charging_current= 3000 mA
 *     battery,max_main_limiter_current = 3150 mA  (same for sub)
 *     battery,battery_full_capacity = 4500 mAh
 *     battery,chg_high_temp       = 49.0 C  (recovery 47.0 C)
 *
 * 4.35 V, not 4.2 V (changed 2026-11-14, user's call). 4.35 V is exactly
 * where the bootloader leaves the chip -- measured CNFG_04 = 0x13 on a live
 * device, which decodes to 4350 mV -- so it is the voltage this pack has been
 * charging to all along, and it is still below Samsung's own 4.38 V. An
 * earlier revision of this file used 4.2 V for cell longevity, which was a
 * defensible choice while nothing bound the charger; now that the driver
 * writes this value, 4.2 V would have been a silent ~20% cut in usable
 * capacity the moment the charger started binding.
 *
 * Charge CURRENT is not taken from DT at all: the mainline driver never
 * writes CNFG_02, so the chip keeps whatever it has and policy lives in
 * userspace (rootfs-work/charge/). Both cells stay connected and no limiter
 * is touched from here.
 */
/*
 * Samsung S2DOS05 display sub-PMIC, on a bitbanged i2c bus (TLMM 76/77).
 *
 * Why this is needed for touch: the FTS9CU80F's two rails come from this
 * chip, not from RPMh. Without it the first SPI read of the device ID came
 * back 00 00 00 00 00 -- the controller clocked out fine, MISO just never
 * answered, because the part was unpowered:
 *   fts9cu80f spi0.0: device id 00 00 00 00 00 (chip_id 000000)
 *   fts9cu80f spi0.0: error -ENODEV: no FTS9CU80F found
 *
 * Nothing had to be written: drivers/regulator/s2dos05-regulator.c and the
 * sec-i2c MFD are both already in mainline, and
 * sdm845-samsung-starqltechn.dts drives the identical chip the same way --
 * child nodes must be named exactly ldo1..ldo4/buck, since the driver uses
 * .of_match_full_name on those names under a "regulators" node.
 *
 * The bus is i2c-gpio because the vendor's is: /i2c@52 is compatible =
 * "i2c-gpio" with gpios = <&tlmm 76 0 &tlmm 77 0>. No QUP is involved, so
 * nothing here depends on GENI. Built in, not a module: with
 * deferred_probe_timeout=1 a late module can never satisfy a deferred
 * -EPROBE_DEFER from a regulator consumer.
 *
 * ldo1/ldo4/buck are the inner panel's vdd3/vci/vddr. XBL left them on and
 * our framebuffer is living off them, so they are declared always-on with
 * NO voltage constraints -- enough to stop anything disabling them, while
 * never reprogramming a voltage out from under a display we cannot
 * re-initialise.
 */
/*
 * MAIN Samsung S2MPB02, vendor /i2c@51 (i2c-gpio, TLMM 78 SDA / 79 SCL),
 * chip at 0x59. Its LDO8 is the 1.8 V "dvdd" of the sensors (vendor
 * digital_hall dvdd-supply, regulator-always-on + boot-on). The bus is
 * declared BARE on purpose: no child node, so no driver binds and nothing
 * here can change a rail. It exists so the chip can be inspected and poked
 * with i2cget/i2cset -f while working out which rail the IMU needs.
 */
/ {
	i2c-main-pmic {
		compatible = "i2c-gpio";
		sda-gpios = <&tlmm 78 (GPIO_ACTIVE_HIGH | GPIO_OPEN_DRAIN)>;
		scl-gpios = <&tlmm 79 (GPIO_ACTIVE_HIGH | GPIO_OPEN_DRAIN)>;
		i2c-gpio,delay-us = <2>;
		pinctrl-names = "default";
		pinctrl-0 = <&main_pmic_i2c>;
		#address-cells = <1>;
		#size-cells = <0>;

		/*
		 * No longer bare (2026-11-13): exactly ONE rail is described,
		 * and s2mpb02-regulator registers only what is described, so
		 * every other rail of this chip still stays as XBL left it.
		 * LDO8 is the 1.8 V dvdd of the fold hall sensor; XBL leaves
		 * it programmed to 1.8 V but off (0x30), Android runs 0xb0.
		 */
		pmic@59 {
			compatible = "samsung,s2mpb02";
			reg = <0x59>;

			regulators {
				s2mpb02_main_l8: ldo8 {
					regulator-name = "sensor_dvdd";
					regulator-min-microvolt = <1800000>;
					regulator-max-microvolt = <1800000>;
				};

				/*
				 * Rear-camera rails (2026-11-15). Taken from
				 * the vendor q2q DTS, where qcom,cam-sensor2
				 * (the IMX258 ultrawide) names exactly these:
				 *   cam_vdig      -> ldo4   1.2  V
				 *   cam_vio       -> ldo6   1.8  V
				 *   cam_vana      -> ldo12  2.7  V
				 *   cam_v_custom1 -> buck2  1.3  V
				 * All four hang off the MAIN S2MPB02, not the
				 * sub one: the camera supplies resolve into the
				 * s2mpb02_pmic@59 under the vendor's i2c@51,
				 * whose pins are TLMM 78/79 -- this bus. The
				 * sub chip is i2c@52 (TLMM 76/77) and carries
				 * the WLAN and cover-panel rails instead.
				 *
				 * ldo4 is a STEP1 LDO: LDO1-5 move in 12.5 mV
				 * steps and LDO6-18 in 25 mV, both from 600 mV
				 * (vendor s2mpb02-regulator.c LDO_DESC table).
				 * Getting that wrong sets a wrong voltage, so
				 * wifi-work/s2mpb02-regulator.c now carries a
				 * separate STEP1 macro for it.
				 */
				s2mpb02_main_l4: ldo4 {
					regulator-name = "cam_vdig_uw";
					regulator-min-microvolt = <1200000>;
					regulator-max-microvolt = <1200000>;
				};

				s2mpb02_main_l6: ldo6 {
					regulator-name = "cam_vio_uw";
					regulator-min-microvolt = <1800000>;
					regulator-max-microvolt = <1800000>;
				};

				s2mpb02_main_l12: ldo12 {
					regulator-name = "cam_vana_uw";
					regulator-min-microvolt = <2700000>;
					regulator-max-microvolt = <2700000>;
				};

				/*
				 * cam_v_custom1. Shared by every rear sensor in
				 * the vendor DT (sensor0/1/2/12 all name it),
				 * i.e. a common rail for the rear camera deck
				 * rather than a per-sensor supply -- and the
				 * upstream imx258 driver only takes vana/vdig/
				 * vif, so no consumer would ever claim it.
				 * always-on for bringup; revisit once the
				 * sensor streams and it can be tested by
				 * removal.
				 */
				s2mpb02_main_b2: buck2 {
					regulator-name = "cam_v_custom1";
					regulator-min-microvolt = <1300000>;
					regulator-max-microvolt = <1300000>;
					regulator-always-on;
				};
			};
		};
	};

	/*
	 * Fold switch: AKM AK09970 digital hall on its own i2c-gpio bus
	 * (vendor /soc/i2c@20: TLMM 104 SDA, 105 SCL, digital_hall@10, INT on
	 * TLMM 80, dvdd = main S2MPB02 LDO8, pull-ups on L2C which is
	 * always-on here). hall-work/ak09970-fold.c programs it with the
	 * vendor thresholds and reports SW_MACHINE_COVER; fold3-fold-watch
	 * turns that into the inner panel's fold_blank.
	 */
	i2c-fold-hall {
		compatible = "i2c-gpio";
		sda-gpios = <&tlmm 104 (GPIO_ACTIVE_HIGH | GPIO_OPEN_DRAIN)>;
		scl-gpios = <&tlmm 105 (GPIO_ACTIVE_HIGH | GPIO_OPEN_DRAIN)>;
		i2c-gpio,delay-us = <5>;
		pinctrl-names = "default";
		pinctrl-0 = <&fold_hall_i2c>, <&fold_hall_default>;
		#address-cells = <1>;
		#size-cells = <0>;

		hall-sensor@10 {
			compatible = "asahi-kasei,ak09970";
			reg = <0x10>;
			int-gpios = <&tlmm 80 GPIO_ACTIVE_HIGH>;
			dvdd-supply = <&s2mpb02_main_l8>;
		};
	};
};

/ {
	i2c_sub_pmic: i2c-sub-pmic {
		compatible = "i2c-gpio";
		sda-gpios = <&tlmm 76 (GPIO_ACTIVE_HIGH | GPIO_OPEN_DRAIN)>;
		scl-gpios = <&tlmm 77 (GPIO_ACTIVE_HIGH | GPIO_OPEN_DRAIN)>;
		i2c-gpio,delay-us = <2>;
		pinctrl-names = "default";
		pinctrl-0 = <&sub_pmic_i2c_sda>, <&sub_pmic_i2c_scl>;
		#address-cells = <1>;
		#size-cells = <0>;

		pmic@60 {
			compatible = "samsung,s2dos05";
			reg = <0x60>;

			regulators {
				s2dos05_ldo1: ldo1 {
					regulator-name = "panel_vdd3";
					regulator-always-on;
				};

				s2dos05_ldo2: ldo2 {
					regulator-name = "tsp_io";
					regulator-min-microvolt = <1800000>;
					regulator-max-microvolt = <1800000>;
					regulator-enable-ramp-delay = <12000>;
					regulator-boot-on;
				};

				s2dos05_ldo3: ldo3 {
					regulator-name = "tsp_avdd";
					regulator-min-microvolt = <3000000>;
					regulator-max-microvolt = <3000000>;
					regulator-enable-ramp-delay = <12000>;
					regulator-boot-on;
				};

				s2dos05_ldo4: ldo4 {
					regulator-name = "panel_vci";
					regulator-always-on;
				};

				s2dos05_buck: buck {
					regulator-name = "panel_vddr";
					regulator-always-on;
				};
			};
		};

		/*
		 * Samsung S2MPB02, "sub" instance. Vendor: /i2c@52/s2mpb02_pmic@59.
		 * THIS is where the QCA6490's core rails come from on q2q -- the
		 * overlay (fragment@189) re-points the generic lahaina cnss
		 * supplies here:
		 *   vdd-wlan-aon + vdd-wlan-dig -> BUCK1, 1.0125 V
		 *   vdd-wlan-rfa2               -> BUCK2, 1.35 V
		 * With them off the chip is electrically absent and the PCIe link
		 * never trains (LnkSta 0x1011); with them on it trains at once.
		 *
		 * No mainline driver: wifi-work/s2mpb02-regulator.c. It registers
		 * ONLY the regulators described here; every other LDO stays as
		 * the bootloader left it (L6/L10/L15 are on for the cover panel).
		 */
		pmic@59 {
			compatible = "samsung,s2mpb02";
			reg = <0x59>;

			regulators {
				s2mpb02_sub_b1: buck1 {
					regulator-name = "wlan_aon_dig";
					regulator-min-microvolt = <1012500>;
					regulator-max-microvolt = <1012500>;
				};

				s2mpb02_sub_b2: buck2 {
					regulator-name = "wlan_rfa2";
					regulator-min-microvolt = <1350000>;
					regulator-max-microvolt = <1350000>;
				};

				/*
				 * "subsensor_vdd": the LSM6DSO IMUs' supply.
				 * Vendor qcom,ssc@5c00000 holds it while the
				 * SLPI runs; XBL leaves it off. Proven by
				 * toggling: off -> "No 'accel' sensor
				 * available", on -> accel data, and the
				 * stk3a9x proximity driver stops hanging the
				 * SLPI. always-on because mainline's PAS
				 * driver has no supply to hang it on.
				 */
				/*
				 * Cover panel rails. XBL leaves all three ON
				 * (L6 0xac, L10 0xb0, L15 0xe0), so, as with
				 * the inner panel's s2dos05 rails: always-on
				 * and NO voltage constraints -- nothing may
				 * reprogram or drop them.
				 */
				s2mpb02_sub_l6: ldo6 {
					regulator-name = "panel_vddr_sub";
					regulator-always-on;
				};

				s2mpb02_sub_l10: ldo10 {
					regulator-name = "panel_vdd3_sub";
					regulator-always-on;
				};

				s2mpb02_sub_l15: ldo15 {
					regulator-name = "panel_vci_sub";
					regulator-always-on;
				};

				s2mpb02_sub_l9: ldo9 {
					regulator-name = "subsensor_vdd";
					regulator-min-microvolt = <1800000>;
					regulator-max-microvolt = <1800000>;
					regulator-always-on;
				};
			};
		};
	};
};

/ {
	battery: battery {
		compatible = "simple-battery";
		voltage-max-design-microvolt = <4350000>;
		voltage-min-design-microvolt = <3400000>;
		charge-full-design-microamp-hours = <4500000>;
	};
};

/*
 * Ask SCM to deactivate the bootloader's secure watchdog.
 *
 * The APSS watchdog block is unreachable by MMIO (see below), but Samsung's
 * own kernel never touches it directly either -- it goes through TrustZone:
 *   drivers/soc/qcom/qcom_wdt_core.c:550  qcom_scm_sec_wdog_deactivate()
 *   SVC 0x01 (BOOT) / CMD 0x07 / owner SIP / args[0] = 1
 *
 * Mainline's qcom_scm has no 0x07 command at all, so it has been patched in
 * (patches/0001-qcom_scm-sec-wdog-deactivate.patch). This property opts us in.
 */
&{/firmware/scm} {
	qcom,disable-sec-wdog;
};

/*
 * NO watchdog node. The APSS watchdog block at 0x17c10000 is UNREACHABLE from
 * the non-secure world on this device.
 *
 * Proven twice, from two different execution contexts:
 *   - uniLoader late_init read/wrote 0x17c10008 in bare metal: attempts 7 and
 *     8 died there with a blackscreen, before Linux ever started.
 *   - qcom_wdt_probe's readl() of WDT_STS/WDT_EN took a synchronous external
 *     abort (ESR 0000000096000010, DFSC 0x10 -- the bus refused it, the MMU
 *     mapping was fine), panicking init:
 *         pc : qcom_wdt_probe+0x338/0x3cc
 *         Kernel panic - not syncing: Attempted to kill init!
 *
 * Samsung's downstream DT does carry qcom,wdt@17c10000 and their kernel uses
 * it, so the block is presumably unlocked for them by firmware we do not
 * invoke. Until that handshake is understood, nothing may touch this address.
 *
 * Consequence: the watchdog stays armed and we cannot pet it. Stage 1 has to
 * complete inside its bite window.
 */

/*
 * UFS stays off for Stage 1. Note upstream sagami also disables it, so SM8350
 * UFS is not a solved problem in mainline yet (a patch enabling it on sagami
 * was under review as of 2026). We boot from an initramfs instead, which
 * removes storage from the list of things that can go wrong on first boot.
 */
/*
 * max77705 PMIC / charger, on qupv3_se7_i2c (i2c@99c000) per the merged
 * post-ABL DT we pulled off the device. Two slave addresses on one chip:
 * 0x66 is the MFD, 0x69 is the charger. IRQ is TLMM GPIO 5, which is why
 * that line had to come out of gpio-reserved-ranges above.
 */
/*
 * The QUP wrapper must be enabled too. Enabling &i2c7 alone does nothing:
 * i2c@99c000 lives inside geniqup@9c0000, and a disabled parent means the
 * child node is never instantiated at all -- no platform device, no i2c bus,
 * no max77705. Cost me a boot to notice.
 */
&qupv3_id_0 {
	status = "okay";
};

/*
 * qup6 i2c (i2c@998000). Enabled 2026-11-14 for the camera EEPROM probe.
 *
 * Deliberately BARE -- no child nodes, exactly like the main S2MPB02 bus. The
 * only thing on it that we care about is qcom,eeprom11, a camera module
 * calibration EEPROM at 7-bit 0x51 (vendor slave-addr = <0xa2>, 8-bit). There
 * is no mainline driver for a Qualcomm camera cal EEPROM, and binding `at24`
 * to it would be a guess about size and page layout, so it gets read with
 * i2cdetect/i2cdump instead. Same reasoning as /i2c@51.
 *
 * It needs ONE rail: cam_vio = s2mpb02-ldo7, which the main S2MPB02 on i2c-0
 * already exposes. From userspace, after boot:
 *
 *     i2cget -f -y 0 0x59 0x24        # LDO7 CTRL, expect 0x30 (1.8 V, off)
 *     i2cset -f -y 0 0x59 0x24 0xb0   # bit 7 = enable -> 1.8 V on
 *     i2cdetect -y -r <bus>           # look for 0x51
 *     i2cdump -y <bus> 0x51
 *     i2cset -f -y 0 0x59 0x24 0x30   # rail back off when done
 *
 * (LDOn CTRL = 0x1e + (n-1). That map was off by one for most of a day once;
 * HANDBOOK section 20 has the story. LDO6-18 are 600 mV + 25 mV * sel.)
 *
 * No pinctrl stanza and no clock-frequency override: upstream's i2c6 node
 * already points at qup_i2c6_default (gpio28/29, function "qup6"), which
 * matches the vendor's qupv3_se6_i2c_active exactly. gpi_dma0 is already
 * okay below, so the dmas property resolves the same way i2c7's does.
 *
 * NOT included here: i2c2 / qup2 (i2c@988000, TLMM 12/13)
 * carries qcom,ois@51, the OIS MCU at 7-bit 0x62. That one wants four rails
 * plus GPIO 173 (MCU_RESET0) and 168 (MCU_BOOT0) sequenced, so it is a worse
 * first test and a separate flash.
 */
&i2c6 {
	status = "okay";
	clock-frequency = <400000>;
};

&i2c7 {
	status = "okay";
	clock-frequency = <400000>;

	/*
	 * The MFD core. It does NOT bind on this unit: mainline's max77705.c
	 * refuses any revision but PASS3 ("Rev.0x%x is not tested") and ours
	 * reads PMICREV = 0x02, i.e. PASS2. Left in place because it costs
	 * nothing, documents the chip, and is where a future revision-gate fix
	 * would land.
	 *
	 * No interrupt property, deliberately. It used to carry
	 * <&tlmm 5 IRQ_TYPE_LEVEL_LOW>, which was simply wrong -- the INTB line
	 * is PM8350C GPIO 5, not TLMM 5 (see the charger node below). Rather
	 * than correct it here, it is removed: the charger owns that line now,
	 * and regmap-irq does not request its parent IRQ shared, so if this node
	 * ever starts binding as well, whichever device probes second would fail
	 * with -EBUSY. If the revision gate is ever relaxed, the right fix is to
	 * let THIS node own INTB and hand the charger a virq out of its
	 * INTSRC domain, the way the chip is actually wired.
	 */
	pmic@66 {
		compatible = "maxim,max77705";
		reg = <0x66>;
		interrupt-controller;
		#interrupt-cells = <1>;
	};

	/*
	 * Fuel gauge. Mainline's max17042_battery already lists
	 * "maxim,max77705-battery", so no new driver is needed.
	 *
	 * NOT read-only without the shunt property, despite what this comment
	 * used to claim. max17042_init_chip() is indeed skipped (no
	 * maxim,config-data), but probe has a second write path: with no
	 * sense resistor described it does
	 *     CGAIN = 0, MiscCFG = 0x0003, LearnCFG = 0x0007
	 * i.e. it switches the gauge to voltage-only mode. The gauge is
	 * battery-backed, so that survived every reboot: Current read 0,
	 * capacity came from VFSOC (103%), and stock's reset workaround had
	 * already thrown the learned capacity away once.
	 *
	 * Stock values, from the 2026-11-07 capture's [FG] register dumps,
	 * were restored by hand on 2026-11-11:
	 *     CGAIN 0x0400 (0x03fb while charging), MiscCFG 0x3870,
	 *     LearnCFG 0x2476
	 *
	 * The shunt is 5 mOhm: vendor fuelgauge,fg_resistor = <2> (10 mOhm
	 * / 2) and "1.5625uV/0.005Ohm(Rsense) = 312.5uA" in the driver.
	 * Describing it stops the clobbering, exposes current_now, switches
	 * capacity to RepSOC and corrects the charge_* scaling (x2).
	 *
	 * Still written at probe: SALRT_Th = 0xff00 (alerts off, because no
	 * irq is wired; stock had 0xff01). Benign. FullSOCThr is untouched
	 * (reads 0x5900, same as stock).
	 *
	 * No interrupt wired: the ALRT pin would mean freeing another GPIO,
	 * and polling is perfectly adequate for a percentage readout.
	 *
	 * 0x36 is the Maxim ModelGauge convention (8-bit 0x6c >> 1), matching
	 * how the charger sits at 0x69 (8-bit 0xd2 >> 1).
	 */
	fuel-gauge@36 {
		compatible = "maxim,max77705-battery";
		reg = <0x36>;
		monitored-battery = <&battery>;
		shunt-resistor-micro-ohms = <5000>;
	};

	/*
	 * Charger. ENABLED 2026-11-14, replacing the userspace i2c poking in
	 * rootfs-work/charge/ with a real power_supply device.
	 *
	 * The precondition the old comment here set -- "once the s2asl01
	 * limiters can be read" -- is met: both answer and their per-cell
	 * telemetry sums to the gauge's pack current (main 0x38 on the
	 * i2c1-derived bus, sub 0x39 on the i2c9 one; 122 + 152 mA vs. the
	 * gauge's 263 mA, cells within 7 mV, 2026-11-14). Each limiter is
	 * independently capped at 900 mA/cell in CTRL4, so whatever this driver
	 * is asked for, total pack current is bounded by hardware at 1800 mA.
	 *
	 * Despite being a child of the MFD's bus this is a plain i2c driver
	 * with its own compatible, so it binds without the MFD above. Built as
	 * a MODULE (CONFIG_CHARGER_MAX77705=m) on purpose: nothing claims the
	 * chip until modprobe, so a mistake here cannot cost a boot.
	 *
	 * INTB is PM8350C GPIO 5, from the vendor DT's
	 *     max77705,irq-gpio = <&pm8350c_gpios 5 GPIO_ACTIVE_LOW>
	 * plus its if_pmic_irq pinctrl node (pins = "gpio5", input-enable,
	 * bias-disable, power-source = <1>) under pm8350c's pinctrl@8800. The
	 * interrupt specifier for spmi-gpio is 1-based -- pmic_gpio_domain_translate()
	 * subtracts PMIC_GPIO_PHYSICAL_OFFSET -- so 5 here means the pad the
	 * vendor calls gpio5, matching how key-volume-up already uses
	 * <&pm8350_gpios 6>. The pinctrl state is NOT optional: XBL leaves this
	 * pad with a 10 uA pull-down on VIN0 reading low, and INTB is
	 * active-low, so without bias-disable a level-low IRQ is asserted
	 * forever.
	 *
	 * What binding this driver writes at probe, measured against the live
	 * chip beforehand so there are no surprises: float voltage from the
	 * battery node (4.35 V = what it already is), top-off 200 -> 150 mA,
	 * BAT-to-SYS overcurrent disabled -> 4.8 A, switching 3 -> 1.5 MHz,
	 * VCHGIN 4.7 -> 4.5 V, CNFG_09 bit 7 (charge enable, which the vendor
	 * driver also sets) 0 -> 1, and the charger watchdog left off. It does
	 * NOT write charge current or input limit, so neither changes at probe.
	 */
	charger@69 {
		compatible = "maxim,max77705-charger";
		reg = <0x69>;
		monitored-battery = <&battery>;
		interrupts-extended = <&pm8350c_gpios 5 IRQ_TYPE_LEVEL_LOW>;
		pinctrl-names = "default";
		pinctrl-0 = <&if_pmic_irq_default>;
	};
};

/*
 * Buses of the two S2ASL01 battery current limiters. Vendor:
 *   qupv3_se1_i2c (i2c@984000) / s2asl01-limiter-main@38
 *   qupv3_se9_i2c (i2c@a84000) / s2asl01-limiter-sub@39  (+ sx9360 grip @28)
 *
 * Deliberately NO client nodes: nothing binds, nothing writes. The buses
 * exist so the limiters can be read with i2c-dev, to learn whether they keep
 * stock's configuration under our kernel before any charger work.
 *
 * The enable/detect GPIOs (86, 74, 167, 131, 132) are NOT claimed anywhere and
 * must stay that way: the bootloader leaves 86 and 167 driven low (= cells
 * connected), measured 2026-11-12.
 *
 * i2c9 lives in the second QUP wrapper, which nothing else used so far.
 * gpi_dma1 is left disabled on purpose: if SE9 turns out to be FIFO-disabled
 * like spi4, i2c9 will defer with "Failed to get tx DMA ch" and that is the
 * next step, not a guess to make now.
 */
&i2c1 {
	status = "okay";
	clock-frequency = <100000>;
};

&qupv3_id_1 {
	status = "okay";
};

&i2c9 {
	status = "okay";
	clock-frequency = <100000>;
};

/*
 * UFS. Off for Stage 1; on now because it is the last piece of a hands-free
 * flash loop -- with storage the shell can dd a new boot.img onto the boot
 * partition itself, and "poweroff -f" power-cycles straight into it (VBUS
 * present makes ABL power the device back on). No buttons, no Download Mode.
 *
 * Supplies and the reset line follow sm8350-hdk / mtp / surface-duo2, which
 * all agree. Sony sagami disables UFS, so it is no help here.
 */
&ufs_mem_hc {
	status = "okay";

	reset-gpios = <&tlmm 203 GPIO_ACTIVE_LOW>;

	vcc-supply = <&pm8350_l7>;
	vcc-max-microamp = <800000>;
	vccq-supply = <&pm8350_l9>;
	vccq-max-microamp = <900000>;
	vdd-hba-supply = <&pm8350_l9>;
};

&ufs_mem_phy {
	status = "okay";

	vdda-phy-supply = <&pm8350_l5>;
	vdda-pll-supply = <&pm8350_l6>;
};

/*
 * USB 2.0, peripheral only -- the same deliberate reduction upstream
 * sm8450-samsung-r0q.dts makes. Gives us a USB gadget (and therefore networking
 * and a shell) without bringing up the SS PHY.
 */
&usb_1 {
	/*
	 * Glue node (qcom,sm8350-dwc3). With no SuperSpeed PHY in play, the glue
	 * must take UTMI as its pipe clock.
	 */
	qcom,select-utmi-as-pipe-clk;

	status = "okay";
};

&usb_1_dwc3 {
	/*
	 * Core node (snps,dwc3). phys/phy-names live HERE, not on the glue --
	 * sm8350.dtsi declares them on this node. Overriding them on &usb_1
	 * silently does nothing and leaves usb3-phy attached, which is exactly
	 * the mistake the first draft of this file made.
	 *
	 * (Upstream sm8450-samsung-r0q.dts sets dr_mode, maximum-speed and phys
	 * on &usb_1. Upstream sm8350-sony-xperia-sagami.dtsi sets dr_mode on
	 * &usb_1_dwc3. We follow sagami: same SoC, and it matches where
	 * sm8350.dtsi actually declares the properties.)
	 */
	/*
	 * "otg", not "peripheral" (2026-11-14). This unit has no working
	 * speaker, so the USB-C port is the only audio output it can have and
	 * it has to be able to host a USB DAC. Needs
	 * CONFIG_USB_DWC3_DUAL_ROLE=y -- with the gadget-only build dwc3 has no
	 * host half at all.
	 *
	 * usb-role-switch is the ONLY workable mechanism on this board:
	 * dwc3_drd_init() takes it first, and its only alternatives are an
	 * extcon (we have none -- no usb-connector node, no VBUS sense) and the
	 * OTG block's ID pin, which Type-C does not wire. With the switch,
	 * userspace gets /sys/class/usb_role/<sw>/role.
	 *
	 * role-switch-default-mode keeps boot behaviour bit-for-bit as it was:
	 * dwc3_setup_role_switch() calls dwc3_set_mode(DEVICE) before
	 * registering the switch, so the g_serial console still comes up exactly
	 * as under dr_mode = "peripheral". The legacy qcom glue also still
	 * enables its QSCRATCH VBUS override, because it only skips that for
	 * dr_mode == "host" (dwc3-qcom-legacy.c: mode != USB_DR_MODE_HOST).
	 *
	 * Switching to host tears the gadget down (__dwc3_set_mode ->
	 * dwc3_gadget_exit), and gserial_free_line() then WAITS for every open
	 * fd on ttyGS0. Stop serial-getty@ttyGS0 first or the switch wedges
	 * userspace -- see HANDBOOK, and never do it while /dev/console resolves
	 * to ttyGS0.
	 */
	dr_mode = "otg";
	usb-role-switch;
	role-switch-default-mode = "peripheral";
	maximum-speed = "high-speed";

	/* drop the SuperSpeed PHY */
	phys = <&usb_1_hsphy>;
	phy-names = "usb2-phy";
};

&usb_1_hsphy {
	vdda-pll-supply = <&pm8350_l5>;
	vdda18-supply = <&pm8350c_l1>;
	vdda33-supply = <&pm8350_l2>;

	status = "okay";
};

/*
 * DisplayPort over USB-C (2026-11-19). Video out to a TV, which with no
 * working speaker on this unit is the only way it will ever drive a screen
 * and a sound system at once.
 *
 * There is no new SoC-side code in this at all. sm8350.dtsi already wires the
 * whole path and upstream already ships every driver:
 *
 *   dpu_intf0 --> mdss_dp (ae90000) --> usb_1_qmpphy DP half (88e8000) --> CC
 *
 * What was missing was only that both nodes ship status = "disabled", plus
 * the two supplies, which the board has to name.
 *
 * WHY THIS DOES NOT ENDANGER THE PANELS. intf0 is the DP interface and
 * nothing else: the inner S6E3XA2 is DSI-1 and the cover S6E3FAB is DSI-2, on
 * intf1/intf2. Enabling mdss_dp adds a third encoder to the same DRM device
 * and touches neither DSI link. The combo PHY is likewise disjoint from the
 * USB2 path we actually use -- &usb_1_dwc3 keeps phys = <&usb_1_hsphy> and
 * maximum-speed = "high-speed", so dwc3 never asks this PHY for anything and
 * the g_serial console is unaffected. (It is also why DP gets TWO lanes, not
 * four: see data-lanes below.)
 *
 * Supplies, from the vendor DT's ssphy@88e8000 rather than from a guess:
 *   vdd-supply   = <&pm8350_l1>, qcom,vdd-voltage-level 0xdea80 = 912000 uV
 *   core-supply  = <&pm8350_l6>, the shared 1.2 V rail (also UFS PHY PLL)
 * sm8350-hdk names the same two rails for the same node, independently.
 */
/*
 * The DP connector at the end of the bridge chain. THIS NODE IS NOT OPTIONAL
 * AND ITS ABSENCE IS FATAL TO THE WHOLE DISPLAY -- it cost one dark-screen
 * flash cycle on 2026-11-19 to learn why.
 *
 * The chain msm_dp needs is:
 *
 *   mdss_dp  --port@1-->  usb_1_qmpphy  --port@0-->  a drm_bridge
 *
 * msm_dp_display_probe_tail() resolves its end of it with
 * devm_drm_of_get_bridge(np, 1, 0), which lands on usb_1_qmpphy because
 * qmp_combo_probe() calls drm_aux_bridge_register() UNCONDITIONALLY and that
 * registers a transparent bridge carrying the PHY's own of_node. But the
 * transparent bridge then demands a next bridge of its own:
 *
 *   data->next_bridge = devm_drm_of_get_bridge(&auxdev->dev, of_node, 0, 0);
 *   if (IS_ERR(data->next_bridge))
 *           return dev_err_probe(...);         // aux-bridge.c
 *
 * i.e. port@0 of the PHY -- usb_1_qmpphy_out -- must point at something that
 * provides a bridge. Leave it dangling and the transparent bridge fails to
 * probe, so of_drm_find_bridge() finds nothing for the PHY node, so
 * devm_drm_of_get_bridge() hands mdss_dp -EPROBE_DEFER forever:
 *
 *   platform ae90000.displayport-controller: deferred probe pending: (reason unknown)
 *
 * and because mdss_dp is a COMPONENT of the one msm DRM device, the component
 * master never completes and NO DRM DEVICE IS CREATED AT ALL. Both DSI panels
 * go with it. /sys/class/drm holds only `version`, msm.ko sits at refcount 0,
 * and the phone has no screen. (The "DSI PLL(n) lock failed" WARNs in that
 * boot are a RED HERRING -- a known-good boot logs four of them too.)
 *
 * Upstream boards never hit this because port@0 goes to their
 * `usb-c-connector`, whose terminating HPD bridge a Type-C port driver
 * creates with devm_drm_dp_hpd_bridge_alloc(). We have no such driver yet, so
 * fold3-dp-hpd.c provides the same bridge on its own DT node instead.
 *
 * Whatever terminates this chain MUST be built in. A module that has not
 * loaded yet is indistinguishable from a missing bridge, and the cost is the
 * entire display, not just DP.
 *
 * When the max77705 Type-C driver lands it should own that bridge and drive
 * it from the sink's DP Status VDMs, replacing the sysfs switch.
 */
/ {
	/*
	 * UPDATED 2026-11-19, second pass: this started as an upstream
	 * `dp-connector`, which did terminate the chain and brought card0-DP-1
	 * up with both panels intact -- but it can only ever report
	 * "disconnected", because a dp-connector has no way to deliver HPD.
	 * DisplayPort Alt Mode has no HPD wire; the sink reports hot-plug
	 * in-band in a DP Status VDM, and msm_dp refuses to even look at the
	 * sink until something tells it so:
	 *
	 *	ret = msm_dp_aux_is_link_connected(priv->aux);
	 *	if (!priv->plugged && !ret)
	 *		goto end;		<- "aux not connected"
	 *
	 * and that function reads the DP controller's own HPD state machine,
	 * which nothing drives on USB-C. Measured: aux link status 0, and the
	 * dock's own DP Status VDM reporting hpd=0 as well.
	 *
	 * So the terminator has to be a real HPD bridge. drivers/gpu/drm/
	 * bridge/fold3-dp-hpd.c is that bridge plus a sysfs switch, and its
	 * header explains the rest. Built IN, never a module: see below.
	 */
	dp_hpd: dp-hpd-bridge {
		compatible = "fold3,dp-hpd-bridge";

		port {
			dp_hpd_in: endpoint {
				remote-endpoint = <&usb_1_qmpphy_out>;
			};
		};
	};
};

&usb_1_qmpphy_out {
	remote-endpoint = <&dp_hpd_in>;
};

&usb_1_qmpphy {
	vdda-phy-supply = <&pm8350_l1>;
	vdda-pll-supply = <&pm8350_l6>;

	/*
	 * sm8350.dtsi already sets orientation-switch; mode-switch is the other
	 * half, and together they make the PHY register a typec_switch and a
	 * typec_mux for a Type-C port driver to drive.
	 *
	 * With NO driver registered to drive them -- which is the state until
	 * the max77705 Type-C driver lands -- this is deliberately inert rather
	 * than broken: qmp_combo_probe() leaves qmpphy_mode at
	 * QMPPHY_MODE_USB3DP and orientation at TYPEC_ORIENTATION_NONE, and
	 * NONE means `reverse = false`, i.e. the normal (CC1) lane mapping. So
	 * DP comes up in combo mode on two lanes in the normal orientation,
	 * which is exactly what a cable inserted one way up wants. Plugged the
	 * other way up the lanes are swapped and the link will not train --
	 * flip the plug, or poke SW_PORTSELECT (see fold3-dp).
	 */
	mode-switch;

	status = "okay";
};

&mdss_dp {
	status = "okay";
};

&mdss_dp_out {
	/*
	 * TWO lanes, i.e. DP pin assignment D, which is what every upstream
	 * Qualcomm phone does (qcm6490-fairphone-fp5, sm8350-hdk, sm8550-mtp
	 * all set <0 1>). Four lanes would need the PHY reconfigured to
	 * QMPPHY_MODE_DP_ONLY through typec_mux_set(), and that call is a no-op
	 * until some PHY half has been initialised
	 * (qmp_combo_typec_mux_set: `if (!qmp->init_count) return 0`), so on a
	 * board with no USB3 consumer the mode at DP-configure time is still
	 * USB3DP. Two lanes needs no mux call at all and cannot get out of step
	 * with what we told the sink.
	 *
	 * It is also plenty: 2 x HBR2 is 8.64 Gbit/s raw, ~6.9 Gbit/s of pixels
	 * after 8b/10b, which covers 1080p60 (3.2) and 4K30 (6.2).
	 */
	data-lanes = <0 1>;

	/*
	 * Capped at RBR (1.62 Gbit/s/lane) for now, 2026-11-19.
	 *
	 * Left uncapped, msm_dp takes the sink's advertised maximum -- this
	 * dock reports MAX_LINK_RATE 0x14 = HBR2 -- and link training fails:
	 *
	 *   msm_dp_ctrl_on_link: rate=540000, num_lanes=2, pixel_rate=50250
	 *   msm_dp_ctrl_setup_main_link: using LINK_BW_SET: 0x14
	 *   msm_dp_link_adjust_levels: lane=0 req_vol_swing=1 ... 2 ... 3
	 *   msm_dp_ctrl_update_phy_vx_px: max. voltage swing level reached 3
	 *   msm_dp_ctrl_link_train_1_2: *ERROR* max v_level reached
	 *   msm_dp_bridge_atomic_enable: *ERROR* Failed link training (rc=-104)
	 *
	 * The sink escalates voltage swing to maximum and still never reaches
	 * channel equalisation. It is marginal rather than dead: one sink IRQ
	 * read reported `channel_eq_done = 0, clock_recovery_done = 1`, so
	 * signal does arrive -- just not cleanly enough at 5.4 Gbit/s through
	 * this dock's captive cable.
	 *
	 * How this is read, so the number is not mysterious:
	 * msm_dp_link_link_frequencies() takes the LAST element of this list
	 * (so keep it ascending) off port@1's endpoint and divides by 10000,
	 * giving msm's units -- 1620000000 -> 162000 = RBR, 2700000000 ->
	 * 270000 = HBR, 5400000000 -> 540000 = HBR2.
	 *
	 * UPDATED 2026-11-20. This was pinned to RBR alone on 2026-11-19
	 * because HBR2 training failed with "max v_level reached". That
	 * diagnosis was wrong, or at least incomplete: we were forcing a
	 * software HPD while the dock still reported HPD_State = 0, and
	 * msm_dp_ctrl_link_train()'s retry loop breaks out early when
	 * msm_dp_aux_is_link_connected() goes false -- which a faked HPD
	 * causes. So training was probably not defeated by signal integrity,
	 * it was defeated by a sink that was not there yet.
	 *
	 * Listing all three is safe, because msm_dp does NOT just try the top
	 * rate and give up. On a training failure dp_ctrl.c steps down:
	 * msm_dp_ctrl_link_rate_down_shift() first, then
	 * msm_dp_ctrl_link_lane_down_shift() once it is already at RBR, all
	 * inside link_train_max_retries. msm_dp_link_link_frequencies() takes
	 * the LAST element as the cap, so this asks for HBR2 and lets the
	 * driver settle wherever the link actually works -- at worst back to
	 * the 2 x RBR that drives 1280x720 today.
	 *
	 * This property does not touch the bridge chain, so it cannot
	 * reproduce the dark-screen failure: the terminating HPD bridge is
	 * built in and present regardless of what is written here.
	 */
	link-frequencies = /bits/ 64 <1620000000 2700000000 5400000000>;
};

/*
 * GPI DMA engine for the QUP0 wrapper. Upstream sm8350.dtsi ships gpi_dma0 as
 * status = "disabled", so the platform device is never created at all --
 * /sys/bus/platform/devices/900000.dma-controller simply does not exist and
 * loading gpi.ko registers no channels (/sys/class/dma stays empty).
 *
 * spi@990000 is NOT optional about this. Its hardware FIFO is disabled
 * (GENI_IF_DISABLE_RO & FIFO_IF_DISABLE), so spi-geni-qcom takes the
 * fifo_disable == 1 path and requires a GPI channel; without one it fails with
 *   platform 990000.spi: deferred probe pending: geni_spi: Failed to get tx DMA ch
 * and no SPI bus is created, so the touchscreen never appears. Deleting the
 * dmas property would NOT help for the same reason.
 *
 * Its IOMMU is apps_smmu, which does work here:
 *   arm-smmu 15000000.iommu: SMMUv2 ... 75 context banks
 *   platform 9c0000.geniqup: Adding to iommu group 0
 * (The arm-smmu probe failure in the log is 3da0000, the GPU's, unrelated.)
 */
&gpi_dma0 {
	status = "okay";
};

/*
 * Inner-display touchscreen: ST FTS9CU80F on spi@990000 (QUP0 SE4 = spi4).
 *
 * The parent wrapper qupv3_id_0 is already enabled above for i2c7, which is
 * required -- a disabled geniqup parent means this child is never
 * instantiated at all.
 *
 * Nothing in mainline claims "st,fts9cu80f": mainline's only ST touch driver
 * is stmfts, which is I2C-only and for the older FTS3BD60/FTM4 generation. So
 * this node deliberately binds NO driver yet. That is the point for now: the
 * SPI device appears, the boot log stays clean, and the controller can be
 * probed from userspace by rebinding it to spidev
 *
 *     echo spidev > /sys/bus/spi/devices/spi*.0/driver_override
 *
 * which works because spidev_probe() only applies its compatible whitelist
 * when device_get_match_data() returns non-NULL. Our own driver then arrives
 * as a module and is iterated over the serial console, no reflash per attempt.
 *
 * Protocol, decoded from Samsung's stm_spi driver in the GPL drop:
 *   write: cmds A0/A2/A4/A7/FA/FB/D0 go out as-is, everything else gets a
 *          0xC0 prefix
 *   read:  3-byte header [0xD1][addr_hi][addr_lo], full duplex, 10us settle,
 *          payload starts 4 bytes in
 *   event: 16 bytes, command 0x87, 12-bit X/Y, touch id in byte 0
 */
&spi4 {
	status = "okay";
	pinctrl-names = "default";
	pinctrl-0 = <&ts_spi_active>, <&ts_cs_active>, <&ts_int_active>;
	cs-gpios = <&tlmm 23 GPIO_ACTIVE_LOW>;

	touchscreen@0 {
		compatible = "st,fts9cu80f";
		reg = <0>;
		spi-max-frequency = <10000000>;
		interrupts-extended = <&tlmm 165 IRQ_TYPE_LEVEL_LOW>;

		/*
		 * vendor: tsp_io_ldo-supply = s2dos05-ldo2 (1.8V digital/IO)
		 *         tsp_avdd_ldo-supply = s2dos05-ldo3 (3.0V analog)
		 * Same split as sdm845-samsung-starqltechn's s6sy761 touch,
		 * which names them vdd and avdd; follow that.
		 */
		vdd-supply = <&s2dos05_ldo2>;
		avdd-supply = <&s2dos05_ldo3>;

		/*
		 * No touchscreen-size-x/y on purpose. The controller reports
		 * its own coordinate space (4095x4095, with a 34x42 channel
		 * grid) via command 0x23, and the driver reads it, so naming a
		 * size here would only add a second source of truth that can
		 * drift from the hardware.
		 *
		 * Orientation, measured on 2026-11-11 with drag gestures:
		 * the bootloader's framebuffer is LANDSCAPE (2208x1768) on a
		 * physically portrait panel, so touch is transposed relative
		 * to the image. Dragging left->right across the display moved
		 * raw Y upward, and dragging top->bottom moved raw X downward:
		 *
		 *     display x =       raw y
		 *     display y = max - raw x
		 *
		 * touchscreen_apply_prop_to_x_y() inverts in raw space first
		 * and swaps afterwards, so that is inverted-x plus swapped-x-y
		 * -- NOT inverted-y, which would mirror it.
		 *
		 * Corner taps could not establish this: with a landscape image
		 * on a portrait panel, "top-left" means two different corners
		 * depending on which one you mean, and no rotation at all fits
		 * the tap sequence they produced. Drags carry their own
		 * direction and are immune to that.
		 */
		touchscreen-swapped-x-y;
		touchscreen-inverted-x;
	};
};

/*
 * PMK8350: power key, volume-down and the RTC.
 *
 * CONFIG_INPUT_PM8941_PWRKEY is already =y and RTC_DRV_PM8XXX=m, so this is a
 * pure DTS change -- no kernel config work.
 *
 * Key codes are the vendor's, read off pon_hlos@1300 in the merged post-ABL
 * DT rather than assumed:
 *   qcom,pon_1  pon-type 0 (KPDPWR)  linux,code = 0x74 = KEY_POWER
 *   qcom,pon_2  pon-type 1 (RESIN)   linux,code = 0x72 = KEY_VOLUMEDOWN
 * Upstream's pmk8350-pwrkey/-resin drivers default to exactly those, so no
 * linux,code override is needed.
 *
 * Note what this implies for suspend: the argument for the staged
 * CONFIG_SUSPEND=n was that there is NO wakeup source, so a suspend can never
 * be undone. pon_pwrkey is that wakeup source. Nothing here enables suspend
 * (the sleep targets stay masked and powerdevil is configured not to ask), but
 * it makes the question testable -- deliberately, and never by accident.
 *
 * logind is already configured HandlePowerKey=poweroff, so once this binds a
 * press cleanly powers the device down instead of doing nothing.
 */
&pon_pwrkey {
	status = "okay";
};

&pon_resin {
	/*
	 * REQUIRED, not cosmetic. pmk8350.dtsi gives pwrkey a linux,code but
	 * gives resin none, and pm8941_pwrkey_probe() falls back to KEY_POWER
	 * for ANY node missing it. Enabling resin bare would therefore make
	 * volume-down report KEY_POWER -- which, with our logind
	 * HandlePowerKey=poweroff, powers the phone off. Every upstream board
	 * that enables resin sets this. 0x72 in the vendor DT = KEY_VOLUMEDOWN.
	 */
	linux,code = <KEY_VOLUMEDOWN>;
	status = "okay";
};

/*
 * RTC, read-only for now.
 *
 * Without an "offset" nvmem cell (or UEFI vars, which we have none of)
 * pm8xxx_rtc_update_offset() returns -ENODEV, so the time cannot be *set*
 * unless the counter itself is writable. `allow-set-time` makes the driver
 * write the counter directly; on many Qualcomm PMICs that register is
 * TZ-owned and the write is dropped, so this is an experiment, not a
 * guarantee. It is harmless either way: the write path is only reached when
 * userspace actually sets the time, and nothing here does so on its own (no
 * network, so timesyncd never fires).
 *
 * The win that matters does not depend on it -- READING a sane boot time
 * fixes the stale clock that made PAM reject plasma-setup with "password
 * changed in the future". See HANDBOOK section 13.
 */
&pmk8350_rtc {
	status = "okay";

	/*
	 * NO allow-set-time. Tried it on 2026-11-11 and the RTC control
	 * register is TZ-owned, so the write never lands:
	 *   spmi spmi-0: disallowed SPMI write to sid=0, addr=0x6146
	 *   hwclock: ioctl(RTC_SET_TIME) ... Operation not permitted
	 * (0x6146 is pmk8350_regs.ctrl.)
	 *
	 * Leaving it in would be worse than useless: with allow_set_time set,
	 * pm8xxx_rtc_set_time() takes the direct-write path and never consults
	 * an offset cell, so it would also defeat the proper fix.
	 *
	 * Reading works, but the counter is not Android's clock -- it holds
	 * ~235000 s (2.7 days), counting from its own last reset, so the boot
	 * clock still needs setting from elsewhere. The upstream answer is an
	 * "offset" nvmem cell in a PMIC SDAM (see sc8280xp boards); that needs
	 * one SDAM enabled and its writability proven, which is its own
	 * experiment. Until then the clock is read-only and wrong.
	 */
};

/*
 * Volume-up. Unlike power and volume-down (PMK8350 PON, above) this one is a
 * plain GPIO key on PM8350 gpio6, active low with the PMIC's own pull-up.
 * From gpio_keys/vol_up + key_vol_up_default in the merged post-ABL DT:
 *   gpios = <&pm8350_gpios 6 1>, linux,code = 0x73 (KEY_VOLUMEUP),
 *   debounce 15 ms, bias-pull-up, power-source = <1>, input-enable.
 * XBL already leaves the pin in exactly that state (debugfs: "in high normal
 * vin-1 pull-up 30uA"), so the pinctrl state restates it rather than changes
 * it. No wakeup-source: suspend is disabled on this device.
 */
/ {
	gpio-keys {
		compatible = "gpio-keys";
		pinctrl-names = "default";
		pinctrl-0 = <&key_vol_up_default>;

		key-volume-up {
			label = "volume_up";
			gpios = <&pm8350_gpios 6 GPIO_ACTIVE_LOW>;
			linux,code = <KEY_VOLUMEUP>;
			debounce-interval = <15>;
		};
	};
};

&tlmm {
	fold_hall_default: fold-hall-default-state {
		pins = "gpio80";
		function = "gpio";
		drive-strength = <2>;
		bias-disable;
	};

	fold_hall_i2c: fold-hall-i2c-state {
		pins = "gpio104", "gpio105";
		function = "gpio";
		drive-strength = <2>;
		bias-disable;
	};
};

&pm8350_gpios {
	key_vol_up_default: key-vol-up-default-state {
		pins = "gpio6";
		function = "normal";
		input-enable;
		bias-pull-up;
		power-source = <1>;
	};
};

/*
 * The max77705's INTB line. Verbatim from the vendor's if_pmic_irq node under
 * qcom,pm8350c@2/pinctrl@8800, including power-source = <1> (VIN1, where XBL
 * leaves this pad on VIN0) and bias-disable: the pull-up is on the board, and
 * the 10 uA internal pull-down XBL leaves behind holds an active-low line
 * permanently asserted.
 */
&pm8350c_gpios {
	if_pmic_irq_default: if-pmic-irq-default-state {
		pins = "gpio5";
		function = "normal";
		input-enable;
		bias-disable;
		power-source = <1>;
	};
};

/*
 * pmk8350.dtsi's nodes have NO status line of their own, so merely including
 * the file would enable all of them. We turn on only what we use:
 *   pmk8350_vadc    SPMI ADC7  -- ENABLED below, for the pack thermistors
 *   pmk8350_gpios   4 PMIC GPIOs
 *   11 SDAMs        PMIC scratch RAM
 * The root-level reboot-mode node goes with the SDAMs: it is nvmem-reboot-mode
 * pointing at a cell inside pmk8350_sdam_2, and would dangle with that SDAM
 * disabled. We force TWRP through the misc-partition BCB instead, which is
 * independent of it (see section 6 / force-TWRP-via-BCB).
 *
 * ADC7's controller lives on PMK8350 (SID 0) but reads other PMICs' channels,
 * addressed as sid << 8 | channel. The two below are the battery pack
 * thermistors, taken from the vendor DT (q2q_eur_openx_w00_r05.dts line 178:
 * io-channel-names "adc-temp" = 0x14b, "adc-sub-bat" = 0x14c) -- i.e. PM8350
 * (SID 1) GPIO2 and GPIO3 with the 100 kOhm pull-up. The pack is dual-cell
 * and has one thermistor per side.
 *
 * Samsung reads these and WRITES the result into the fuel gauge, which is why
 * the gauge's own temperature register is a frozen constant on mainline:
 * nothing here was feeding it. See HANDBOOK 29.6 item 1b.
 *
 * Default scaling for a *_100K_PU channel is SCALE_HW_CALIB_THERM_100K_PULLUP,
 * so these read as temperature off Qualcomm's generic 100k NTC curve. The
 * vendor's own 23-point table (battery,temp_table_adc / _data) is in the
 * vendor DT if the two curves disagree.
 */
&pmk8350_vadc {
	status = "okay";

	channel@14b {
		reg = <PM8350_ADC7_GPIO2_100K_PU(1)>;
		qcom,ratiometric;
		qcom,hw-settle-time = <200>;
		qcom,pre-scaling = <1 1>;
		label = "batt_therm";
	};

	channel@14c {
		reg = <PM8350_ADC7_GPIO3_100K_PU(1)>;
		qcom,ratiometric;
		qcom,hw-settle-time = <200>;
		qcom,pre-scaling = <1 1>;
		label = "sub_batt_therm";
	};
};

&pmk8350_gpios {
	status = "disabled";
};

&pmk8350_sdam_1 { status = "disabled"; };
&pmk8350_sdam_2 { status = "disabled"; };
&pmk8350_sdam_5 { status = "disabled"; };
&pmk8350_sdam_13 { status = "disabled"; };
&pmk8350_sdam_14 { status = "disabled"; };
&pmk8350_sdam_21 { status = "disabled"; };
&pmk8350_sdam_22 { status = "disabled"; };
&pmk8350_sdam_23 { status = "disabled"; };
&pmk8350_sdam_41 { status = "disabled"; };
&pmk8350_sdam_46 { status = "disabled"; };

&{/reboot-mode} {
	status = "disabled";
};

/*
 * Wi-Fi: QCA6490 on pcie0.
 *
 * No driver work: QCA6490 shares PCI ID 17cb:1103 with WCN6855, and ath11k
 * demultiplexes that ID from the chip's own version registers. This silicon
 * reports major 2 / minor 0x00-0x01 (evidence: /vendor/firmware/qca6490 ships
 * amss20.bin and NO amss.bin, which downstream cnss2 only picks for
 * major == 2; BT ships hpbtfw20.tlv; PCI revision byte 0x01), which lands on
 * ATH11K_HW_WCN6855_HW20 unmodified. See "Hard Truths/12-wifi-qca6490.md".
 *
 * The chip must be powered BEFORE PCIe enumeration, which is what the
 * wcn6855-pmu + pci-pwrctrl-pwrseq pair does: the PMU drives wlan-en/bt-en,
 * exposes the chip's internal LDOs as regulators, and pwrctrl then triggers a
 * bus rescan so the endpoint appears. Both are built in, because
 * deferred_probe_timeout=1 kills anything that defers waiting on a module.
 *
 * Rail mapping is the q2q OVERLAY's (fragment@189), which overrides the
 * generic lahaina.dtsi one this file used to copy:
 *   vdd-wlan-io    S10B              -> pm8350_s10      1.8 V
 *   vdd-wlan-aon   S2MPB02 sub BUCK1 -> s2mpb02_sub_b1  1.0125 V
 *   vdd-wlan-dig   S2MPB02 sub BUCK1 -> s2mpb02_sub_b1  1.0125 V
 *   vdd-wlan-rfa2  S2MPB02 sub BUCK2 -> s2mpb02_sub_b2  1.35 V
 *   vdd-wlan-rfa1  S1C               -> pm8350c_s1      1.984 V
 *
 * Firmware: use linux-firmware's WCN6855 hw2.0 set (amss/m3/regdb/board-2),
 * uncompressed. Samsung's Android amss20.bin asserts ~1.7 s after WMI init
 * under ath11k, with every one of its four bdwlan files.
 *
 * q2q has NO xo-clk-gpio (absent from both lahaina.dtsi and the q2q overlay),
 * so unlike some QCA6490 boards that property is deliberately omitted.
 */
/ {
	wcn6855-pmu {
		compatible = "qcom,wcn6855-pmu";

		pinctrl-names = "default";
		pinctrl-0 = <&wlan_en_state>, <&bt_en_state>;

		wlan-enable-gpios = <&tlmm 64 GPIO_ACTIVE_HIGH>;
		bt-enable-gpios = <&tlmm 65 GPIO_ACTIVE_HIGH>;
		/*
		 * No swctrl-gpios: the q2q overlay deletes qcom,sw-ctrl-gpio
		 * (and the BT one). gpio153 reads low under a pull-up with the
		 * chip fully working, so it is not that signal on this board.
		 */

		/*
		 * Supplies follow the q2q overlay, NOT generic lahaina.dtsi
		 * (which says S11B/S12B/S2E and is wrong for this board):
		 *   io          S10B              1.8 V
		 *   aon + dig   S2MPB02 sub BUCK1 1.0125 V
		 *   rfa2        S2MPB02 sub BUCK2 1.35 V
		 *   rfa1        S1C               1.984 V
		 */
		vddio-supply = <&pm8350_s10>;
		vddaon-supply = <&s2mpb02_sub_b1>;
		vddpmu-supply = <&s2mpb02_sub_b2>;
		vddpmumx-supply = <&s2mpb02_sub_b1>;
		vddpmucx-supply = <&s2mpb02_sub_b1>;
		vddrfa0p95-supply = <&s2mpb02_sub_b1>;
		vddrfa1p3-supply = <&s2mpb02_sub_b2>;
		vddrfa1p9-supply = <&pm8350c_s1>;
		vddpcie1p3-supply = <&s2mpb02_sub_b2>;
		vddpcie1p9-supply = <&pm8350c_s1>;

		regulators {
			vreg_pmu_rfa_cmn: ldo0 {
				regulator-name = "vreg_pmu_rfa_cmn";
			};

			vreg_pmu_aon_0p59: ldo1 {
				regulator-name = "vreg_pmu_aon_0p59";
			};

			vreg_pmu_wlcx_0p8: ldo2 {
				regulator-name = "vreg_pmu_wlcx_0p8";
			};

			vreg_pmu_wlmx_0p85: ldo3 {
				regulator-name = "vreg_pmu_wlmx_0p85";
			};

			vreg_pmu_btcmx_0p85: ldo4 {
				regulator-name = "vreg_pmu_btcmx_0p85";
			};

			vreg_pmu_rfa_0p8: ldo5 {
				regulator-name = "vreg_pmu_rfa_0p8";
			};

			vreg_pmu_rfa_1p2: ldo6 {
				regulator-name = "vreg_pmu_rfa_1p2";
			};

			vreg_pmu_rfa_1p8: ldo7 {
				regulator-name = "vreg_pmu_rfa_1p8";
			};

			vreg_pmu_pcie_0p9: ldo8 {
				regulator-name = "vreg_pmu_pcie_0p9";
			};

			vreg_pmu_pcie_1p8: ldo9 {
				regulator-name = "vreg_pmu_pcie_1p8";
			};
		};
	};
};

&pcie0 {
	pinctrl-names = "default";
	pinctrl-0 = <&pcie0_default_state>;

	perst-gpios = <&tlmm 94 GPIO_ACTIVE_LOW>;
	wake-gpios = <&tlmm 96 GPIO_ACTIVE_HIGH>;

	status = "okay";
};

&pcie0_phy {
	vdda-phy-supply = <&pm8350_l5>;
	vdda-pll-supply = <&pm8350_l6>;
	status = "okay";
};

/*
 * The endpoint. sm8350.dtsi leaves the pcie0 root port unlabelled, so it is
 * reached by path rather than by phandle.
 *
 * No qcom,ath11k-calibration-variant: ath11k tries board-2.bin (a container
 * indexed by bus/chip/board id) and then falls back to a bare board.bin, and
 * Samsung ships bare BDFs. Installing one as board.bin is the cheaper first
 * attempt; if it is rejected, the BDFs get wrapped with ath11k-bdencoder and
 * a variant string added here.
 */
&{/soc@0/pcie@1c00000/pcie@0} {
	wifi@0 {
		compatible = "pci17cb,1103";
		reg = <0x10000 0x0 0x0 0x0 0x0>;

		vddrfacmn-supply = <&vreg_pmu_rfa_cmn>;
		vddaon-supply = <&vreg_pmu_aon_0p59>;
		vddwlcx-supply = <&vreg_pmu_wlcx_0p8>;
		vddwlmx-supply = <&vreg_pmu_wlmx_0p85>;
		vddrfa0p8-supply = <&vreg_pmu_rfa_0p8>;
		vddrfa1p2-supply = <&vreg_pmu_rfa_1p2>;
		/* 1103 requires vddrfa1p8; vddrfa1p7 is QCA6390 (1101) only */
		vddrfa1p8-supply = <&vreg_pmu_rfa_1p8>;
		vddpcie0p9-supply = <&vreg_pmu_pcie_0p9>;
		vddpcie1p8-supply = <&vreg_pmu_pcie_1p8>;
	};
};

/*
 * ---------------------------------------------------------------------------
 * GPU -- Adreno 660 (a660.1, chip id 0x06060001)
 * ---------------------------------------------------------------------------
 * Everything the SoC needs is already in sm8350.dtsi: gpu@3d00000,
 * gmu@3d6a000, gpucc, adreno_smmu and the OPP tables. Three things made this
 * safe to switch on, and all three are now true:
 *
 *   - adreno_smmu (3da0000.iommu) binds. It used to fail with -110, which
 *     looked like a protected-register problem; it was deferred_probe_timeout
 *     being 1 while gpucc is a module that loads from userspace. At 60 it
 *     binds. Verified on the device, not inferred.
 *   - a660.1 declares no speedbins, so nothing reads a qfprom "speed_bin"
 *     nvmem cell. a6xx_set_supported_hw() treats -ENOENT as "no speedbin
 *     support, fine" and returns 0. Our qfprom is TZ-protected, so a target
 *     that DID need the fuse would be a problem.
 *   - the GMU node has no qcom,qmp and the GPU has no interconnects, so there
 *     is no AOSS or icc dependency to satisfy first.
 *
 * pil_gpu_mem, inherited from sm8350.dtsi at 0x8b51a000 size 0x2000, is byte
 * for byte what Samsung's own lahaina.dtsi reserves, so the zap shader lands
 * where this device's TZ expects it. Its loadable segment is 1976 bytes, well
 * inside the 8 KiB region.
 */
&gpu {
	status = "okay";
};

/*
 * The zap shader takes the GPU out of secure mode; without it the driver
 * cannot write the registers it needs and will not come up.
 *
 * It is SIGNED PER DEVICE FAMILY, so this is Samsung's own blob, pulled off
 * this phone's firmware_mnt (capture/firmware-DATE/firmware_mnt/image.tar) --
 * linux-firmware cannot ship one that this TZ will authenticate.
 *
 * Setting firmware-name makes the driver load the path verbatim with
 * request_firmware_direct() and skip adreno_request_fw()'s qcom/-prefix
 * guessing. The format is the split MDT/Bxx one (a660_zap.mdt + .b00..b02);
 * qcom_mdt_load() derives the segment names from this one by replacing the
 * extension, so all four files must sit in the same directory.
 */
&gpu_zap_shader {
	firmware-name = "qcom/sm8350/samsung/q2q/a660_zap.mdt";
};

/*
 * ---------------------------------------------------------------------------
 * DISPLAY -- MDSS/DPU + DSI0 + the S6E3XA2 inner panel
 * ---------------------------------------------------------------------------
 * This REPLACES simpledrm on the bootloader framebuffer. The two cannot
 * coexist: simpledrm would keep scanning out of the surface XBL left behind
 * while DPU reprograms the display controller underneath it. The
 * framebuffer@e4000000 chosen node is therefore gone, and SM_DISPCC_8250 is
 * now a module -- the thing it used to break (the live bootloader scanout) is
 * exactly what we are now replacing on purpose.
 *
 * Nothing SoC-level was needed: qcom,sm8350-mdss, -dpu, -dsi-ctrl and
 * -dsi-phy-5nm are all upstream and sm8350.dtsi already wires them, including
 * the dpu/dsi OPP tables and the MMCX power domain.
 *
 * Supply assignment follows sm8350-hdk, the SoC reference design:
 *   dsi0 vdda  = L6B 1.2 V   (our pm8350_l6, named vreg_l6b_1p2)
 *   dsi0 phy   = L5B 0.88 V  (our pm8350_l5)
 *
 * splash_region in reserved-memory is deliberately KEPT. The bootloader's
 * framebuffer is no longer used, but leaving the carve-out reserved costs
 * 35 MiB and removes any chance of the kernel allocating into memory the
 * display was still scanning out of during the handover.
 */
&mdss {
	status = "okay";
};

&mdss_dsi0 {
	vdda-supply = <&pm8350_l6>;
	status = "okay";

	panel@0 {
		compatible = "samsung,s6e3xa2-amf755ze01";
		reg = <0>;

		/*
		 * All three rails come off the s2dos05 display sub-PMIC (see
		 * the i2c_sub_pmic node above), NOT off RPMh. They are declared
		 * regulator-always-on there because XBL leaves them on, so
		 * these enables are effectively no-ops -- which is what we
		 * want for a first attempt: the panel is already powered and
		 * only the reset pulse and the init sequence are in question.
		 *
		 * Rail identities are verified from the captured merged
		 * post-ABL DT, where the s2dos05 outputs carry these
		 * regulator-names directly:
		 *   ldo1 "panel_vdd3" 1.8 V logic/VDDI
		 *   buck "panel_vddr" 1.8 V (1.6 V in LPM)
		 *   ldo4 "panel_vci"  3.0 V, 10 ms settle
		 */
		vdd3-supply = <&s2dos05_ldo1>;
		vddr-supply = <&s2dos05_buck>;
		vci-supply  = <&s2dos05_ldo4>;

		/*
		 * NO reset-gpios. This used to say <&tlmm 24>, from the generic
		 * Qualcomm panel nodes (qcom,platform-reset-gpio = 0x18). The
		 * Samsung XA2 node says 0x0e: the reset is tlmm 14
		 * (panel_xa2_ze01_reset_active). tlmm 24/25 are the CS35L41
		 * amps' i2c bus (qup5), which is how this surfaced -- enabling
		 * i2c5 took pin 24 and the panel failed to probe.
		 *
		 * The panel therefore never received a real reset from us and
		 * runs on the bootloader's initialisation. Leaving the line
		 * undescribed keeps exactly that behaviour. Wiring tlmm 14 is
		 * a separate, deliberate experiment (it is also still inside
		 * gpio-reserved-ranges).
		 */
		/* vendor samsung,mipisel-gpio = <&tlmm 0x61 0>, on_val = 1 */
		mipi-sel-gpios = <&tlmm 97 GPIO_ACTIVE_HIGH>;

		pinctrl-names = "default";
		pinctrl-0 = <&panel_te_active>, <&panel_mipisel_active>;

		port {
			panel_in: endpoint {
				remote-endpoint = <&mdss_dsi0_out>;
			};
		};
	};
};

&mdss_dsi0_out {
	remote-endpoint = <&panel_in>;
	data-lanes = <0 1 2 3>;
};

/*
 * COVER DISPLAY: S6E3FAB_AMB623ZF01, 832x2268 command mode + DSC, on the
 * second DSI controller. Driver is out of tree: cover-work/. No touch and no
 * fold switching by design -- it is simply a second output.
 * Both panels need 2 LM + 2 DSC each (DSC merge); SM8350 has exactly 4 DSCs.
 */
&mdss_dsi1 {
	vdda-supply = <&pm8350_l6>;
	status = "okay";

	panel@0 {
		compatible = "samsung,s6e3fab-amb623zf01";
		reg = <0>;

		vdd3-supply = <&s2mpb02_sub_l10>;
		vddr-supply = <&s2mpb02_sub_l6>;
		vci-supply  = <&s2mpb02_sub_l15>;

		reset-gpios = <&tlmm 17 GPIO_ACTIVE_HIGH>;

		pinctrl-names = "default";
		pinctrl-0 = <&cover_te_active>, <&cover_reset_active>;

		port {
			cover_panel_in: endpoint {
				remote-endpoint = <&mdss_dsi1_out>;
			};
		};
	};
};

&mdss_dsi1_out {
	remote-endpoint = <&cover_panel_in>;
	data-lanes = <0 1 2 3>;
	qcom,te-source = "mdp_vsync_s";
};

&mdss_dsi1_phy {
	vdds-supply = <&pm8350_l5>;
	status = "okay";
};

&mdss_dsi0_phy {
	vdds-supply = <&pm8350_l5>;
	status = "okay";
};

/*
 * ---------------------------------------------------------------------------
 * AUDIO, milestone 1: the ADSP only.
 * ---------------------------------------------------------------------------
 * Everything audible hangs off the audio DSP: q6afe/q6asm/q6adm are services
 * inside it, reached over GLINK once it boots. sm8350.dtsi already describes
 * the remoteproc, its smp2p pair and the APR services; this just turns it on
 * and points it at Samsung's signed image (firmware_mnt:/image/adsp.mdt +
 * .bNN, extracted 2026-11-07). No sound card yet.
 *
 * Hardware, for the later milestones (vendor overlay):
 *   speakers  2x Cirrus CS35L41 on i2c + TERT MI2S (qcom,wsa-max-devs = 0)
 *   mics      DMICs on the LPASS VA macro
 *   codec     WCD938x on SoundWire (USB-C analog accessories)
 */
&adsp {
	firmware-name = "qcom/sm8350/samsung/q2q/adsp.mdt";
	status = "okay";
};

/*
 * SENSORS, milestone 1: the SLPI only. Same shape as the ADSP above:
 * sm8350.dtsi already describes the remoteproc, smp2p pair and the "sdsp"
 * fastrpc edge; this points it at Samsung's signed image and the relocated
 * memory region (see pil_slpi_mem). Userspace (hexagonrpcd + libssc) comes
 * after this is seen to boot.
 */
&slpi {
	firmware-name = "qcom/sm8350/samsung/q2q/slpi.mdt";
	status = "okay";
};

/*
 * MODEM (LTE), milestone 1: the MPSS remoteproc only, no IPA data path yet.
 * Samsung's modem.mdt loads at 0x8b800000 and spans 0xf600000 -- inside
 * upstream's pil_modem_mem (0x10000000), and Samsung's own modem_region is
 * that same base, so nothing is relocated. rmtfs_mem (0x9b800000+0x280000)
 * stays upstream's; it ends below uniLoader's 0x9bb00000 payload area.
 * Userspace: rmtfs runs read-only against the real modemst/fsg partitions
 * (Fedora's default unit, -r -P -s), so the modem cannot write the EFS.
 */
&mpss {
	firmware-name = "qcom/sm8350/samsung/q2q/modem.mdt";
	status = "okay";
};

/*
 * MODEM, milestone 2: IPA, the data path. Verified first without it
 * (2026-11-13): modem boots and answers QMI on qrtr node 0. ModemManager
 * only adopts a qrtr modem once the IPA driver provides its network
 * device, so this is also what makes `mmcli -L` show anything.
 * ipa_fws.* comes from Android's /vendor/firmware (not the modem partition).
 */
&ipa {
	firmware-name = "qcom/sm8350/samsung/q2q/ipa_fws.mdt";
	/*
	 * The 7.2 sm8350.dtsi we build against has no memory-region on the
	 * ipa node (newer upstream does); without it the driver fails with
	 * "error -19 getting memory-region" and loads no GSI firmware.
	 */
	memory-region = <&pil_ipa_fw_mem>;
	status = "okay";
};

/*
 * ---------------------------------------------------------------------------
 * AUDIO, milestone 2: speakers.
 * ---------------------------------------------------------------------------
 * Two Cirrus CS35L41 boosted amps on i2c5 (vendor qupv3_se5_i2c):
 *     0x41  "cs35l40-top"   reset = expander pin 18
 *     0x40  "cs35l40-bot"   reset = expander pin 19, cirrus,right-channel-amp
 * Both interrupt on expander pin 10 (shared, open drain from the amps' GPIO2).
 * The WCD938x is absent on this board (qcom,wcd-disabled = <1>) and
 * qcom,wsa-max-devs = <0>, so there is no SoundWire in the playback path.
 *
 * Framing: the vendor runs the bus as PRI TDM (4 x 32-bit slots, 6.144 MHz).
 * Mainline's sm8250 machine driver only knows MI2S, and the pins are the
 * MI2S0 pins either way, so this uses PRIMARY_MI2S_RX: plain stereo I2S,
 * 16-bit, 1.536 MHz. top = left slot, bot = right slot
 * (patches/0006 sets the per-amp clocking and channel map).
 *
 * NO Cirrus DSP firmware is loaded, so there is NO speaker protection.
 * Keep the volume down.
 *
 * Boost: the vendor DT gives only the peak current (4100 mA) and the vendor
 * driver never touches the converter's loop coefficients, i.e. it runs the
 * chip's reset values (K1 = K2 = 0x24, slope 0x75, LBST 0). Mainline insists
 * on an inductor and a capacitor value and derives the coefficients from
 * them; 1000 nH with a capacitor under 20 uF maps to exactly those reset
 * values, so that is what is declared -- it reproduces the vendor's
 * configuration, it is not a measurement of the board.
 */
/ {
	i2c-expander {
		compatible = "i2c-gpio";
		sda-gpios = <&tlmm 171 (GPIO_ACTIVE_HIGH | GPIO_OPEN_DRAIN)>;
		scl-gpios = <&tlmm 172 (GPIO_ACTIVE_HIGH | GPIO_OPEN_DRAIN)>;
		i2c-gpio,delay-us = <2>;
		pinctrl-names = "default";
		pinctrl-0 = <&exp_i2c_state>;
		#address-cells = <1>;
		#size-cells = <0>;

		/*
		 * Vendor "nxp,pca953x" with gpio_num = 24; the vendor driver's
		 * id table names it pcal6524. NO reset-gpios on purpose: the
		 * vendor's line (TLMM 122) would return every pin to an input,
		 * and this chip also carries s2dos05 and panel-detect lines
		 * the bootloader has already set up.
		 */
		gpio_expander: gpio@22 {
			compatible = "nxp,pcal6524";
			reg = <0x22>;
			gpio-controller;
			#gpio-cells = <2>;
			interrupt-controller;
			#interrupt-cells = <2>;
			interrupts-extended = <&tlmm 51 IRQ_TYPE_LEVEL_LOW>;
			pinctrl-names = "default";
			pinctrl-0 = <&exp_irq_state>;
		};
	};

	sound {
		compatible = "qcom,sm8250-sndcard";
		model = "Samsung-Q2Q";
		pinctrl-names = "default";
		pinctrl-0 = <&mi2s0_state>;

		mm1-dai-link {
			link-name = "MultiMedia1";

			cpu {
				sound-dai = <&q6asmdai MSM_FRONTEND_DAI_MULTIMEDIA1>;
			};
		};

		speaker-dai-link {
			link-name = "Speaker Playback";

			cpu {
				sound-dai = <&q6afedai PRIMARY_MI2S_RX>;
			};

			platform {
				sound-dai = <&q6routing>;
			};

			codec {
				sound-dai = <&cs35l41_top 0>, <&cs35l41_bot 0>;
			};
		};
	};
};

&q6afedai {
	dai@16 {
		reg = <PRIMARY_MI2S_RX>;
		qcom,sd-lines = <1>;
	};
};

&i2c5 {
	status = "okay";
	clock-frequency = <400000>;

	cs35l41_bot: speaker-amp@40 {
		compatible = "cirrus,cs35l41";
		reg = <0x40>;
		#sound-dai-cells = <1>;
		sound-name-prefix = "Bottom";
		reset-gpios = <&gpio_expander 19 GPIO_ACTIVE_HIGH>;
		interrupts-extended = <&gpio_expander 10 IRQ_TYPE_LEVEL_LOW>;
		cirrus,boost-peak-milliamp = <4100>;
		cirrus,boost-ind-nanohenry = <1000>;
		cirrus,boost-cap-microfarad = <15>;
		cirrus,asp-sdout-hiz = <3>;
		cirrus,gpio2-src-select = <2>;
		cirrus,gpio2-output-enable;
	};

	cs35l41_top: speaker-amp@41 {
		compatible = "cirrus,cs35l41";
		reg = <0x41>;
		#sound-dai-cells = <1>;
		sound-name-prefix = "Top";
		reset-gpios = <&gpio_expander 18 GPIO_ACTIVE_HIGH>;
		interrupts-extended = <&gpio_expander 10 IRQ_TYPE_LEVEL_LOW>;
		cirrus,boost-peak-milliamp = <4100>;
		cirrus,boost-ind-nanohenry = <1000>;
		cirrus,boost-cap-microfarad = <15>;
		cirrus,asp-sdout-hiz = <3>;
		cirrus,gpio2-src-select = <2>;
		cirrus,gpio2-output-enable;
	};
};

/*
 * ---------------------------------------------------------------------------
 * BLUETOOTH: the BT half of the QCA6490, on UART18.
 *
 * Nothing new on the power side: the wcn6855-pmu node above already owns
 * bt-enable (TLMM 65, vendor qcom,bt-reset-gpio = 0x41) and all the rails, and
 * hci_qca reaches it through the power sequencer because this node has no
 * enable-gpios of its own. The supplies below are the PMU's outputs, which is
 * what makes pwrseq match.
 *
 * Firmware is upstream linux-firmware qca/hpbtfw21.tlv + qca/hpnv21.* and must
 * be UNCOMPRESSED on the rootfs (CONFIG_FW_LOADER_COMPRESS is off).
 * No BD address is provisioned; set one with btmgmt public-addr.
 * ---------------------------------------------------------------------------
 */
/*
 * REQUIRED: qcom_geni_serial takes its line number from a "serial" (or
 * "hsuart") alias and refuses to probe without one --
 * "890000.serial: Invalid line -19". This board had no aliases node at all.
 */
/ {
	aliases {
		serial1 = &uart18;
	};
};

&qupv3_id_2 {
	status = "okay";
};

&uart18 {
	pinctrl-names = "default";
	pinctrl-0 = <&bt_uart_state>;
	status = "okay";

	bluetooth {
		compatible = "qcom,wcn6855-bt";
		max-speed = <3200000>;

		vddrfacmn-supply = <&vreg_pmu_rfa_cmn>;
		vddaon-supply = <&vreg_pmu_aon_0p59>;
		vddwlcx-supply = <&vreg_pmu_wlcx_0p8>;
		vddwlmx-supply = <&vreg_pmu_wlmx_0p85>;
		vddbtcmx-supply = <&vreg_pmu_btcmx_0p85>;
		vddrfa0p8-supply = <&vreg_pmu_rfa_0p8>;
		vddrfa1p2-supply = <&vreg_pmu_rfa_1p2>;
		vddrfa1p8-supply = <&vreg_pmu_rfa_1p8>;
	};
};

/*
 * Camera clock controller (camcc). Added 2026-11-14.
 *
 * Mainline sm8350.dtsi has no camcc node because mainline had no camcc-sm8350
 * driver; camera-work/ now generates one from Qualcomm's camcc-lahaina.c. The
 * node lives here rather than in sm8350.dtsi only so it can be iterated on
 * without carrying a tree patch -- it belongs upstream in the SoC dtsi.
 *
 * Deliberate differences from mainline's sm8250 camcc node:
 *
 *   - NO "iface" clock. sm8250's node takes <&gcc GCC_CAMERA_AHB_CLK>, but
 *     mainline gcc-sm8350.c does not model that clock at all (it has only the
 *     camera hf/sf AXI clocks). Android's own suspend-time clock dump shows
 *     gcc_camera_ahb_clk enabled with nothing holding it, i.e. it is left on,
 *     which is also why our driver needs no runtime PM to touch registers.
 *     See HANDBOOK and camera-work/README.md.
 *   - MMCX is still required: the camcc register block sits in that domain.
 *
 * reg/size come from the vendor DT (qcom,camcc@ad00000, 0x10000), and
 * max_register in the driver is the vendor's 0xf008.
 */
&soc {
	camcc: clock-controller@ad00000 {
		compatible = "qcom,sm8350-camcc";
		reg = <0 0x0ad00000 0 0x10000>;

		clocks = <&rpmhcc RPMH_CXO_CLK>,
			 <&rpmhcc RPMH_CXO_CLK_A>,
			 <&sleep_clk>;
		clock-names = "bi_tcxo", "bi_tcxo_ao", "sleep_clk";

		power-domains = <&rpmhpd RPMHPD_MMCX>;
		required-opps = <&rpmhpd_opp_low_svs>;

		#clock-cells = <1>;
		#reset-cells = <1>;
		#power-domain-cells = <1>;

		status = "okay";
	};
};

&tlmm {
	/*
	 * CAMIF_MCLK3 -> the cover camera module. Values copied from the
	 * vendor's cam_sensor_mclk3_active: function "cam_mclk",
	 * drive-strength 4, bias-disable.
	 */
	cam_mclk3_active: cam-mclk3-active-state {
		pins = "gpio103";
		function = "cam_mclk";
		drive-strength = <4>;
		bias-disable;
	};
};

/*
 * ===========================================================================
 * Cameras, stage 1: CCI1 + camss + the rear ultrawide IMX258 (2026-11-15)
 * ===========================================================================
 *
 * This replaces the temporary `camcc-mclk-test` harness, which existed only so
 * that *something* claimed titan_top_gdsc (a GDSC is a genpd and only powers up
 * for an attached device, so camcc clocks returned -EBUSY with no consumer).
 * The camss node below is that consumer for real.
 *
 * WHY THE ULTRAWIDE, and not the cover module the 11-14 session was chasing:
 * three of this phone's five sensors already have complete upstream drivers --
 * the handbook's "sensor subdevs: none exist upstream" was wrong.
 *
 *     rear ultrawide   SONY IMX258   drivers/media/i2c/imx258.c   <- this node
 *     front            SONY IMX471   drivers/media/i2c/imx471.c
 *     rear tele        S5K3M5        drivers/media/i2c/s5k3m5.c   (dual-sourced
 *                                    with HI1337; which one this unit has is
 *                                    not yet established)
 *
 * That matters because the one genuinely unportable piece is the sensor's init
 * and mode register sequences: Qualcomm keeps them in userspace HAL data, not
 * in the GPL kernel drop. An upstream subdev driver carries its own, so the
 * IMX258 sidesteps the single thing that decides whether this ever captures.
 * It is also 19.2 MHz native (imx258.c accepts 19.2 and 24 MHz) and Android
 * demonstrably streams it, so the module is known good.
 *
 * The ceiling is unchanged: mainline camss is a CSI receiver with no ISP
 * driver, so this yields raw Bayer frames, not One UI output.
 */

&tlmm {
	/*
	 * CCI1's two i2c masters. "cci2/cci3" is the vendor's global numbering
	 * of the four CCI masters (cci0/cci1 = hardware CCI0 m0/m1 on 107-110,
	 * cci2/cci3 = hardware CCI1 m0/m1 on 111-114); the names here follow
	 * mainline's per-controller convention instead. Values are the vendor's
	 * cci2_active/cci3_active: function "cci_i2c", pull-up, 2 mA.
	 */
	cci1_default: cci1-default-state {
		pins = "gpio111", "gpio112", "gpio113", "gpio114";
		function = "cci_i2c";
		bias-pull-up;
		drive-strength = <2>;
	};

	cci1_sleep: cci1-sleep-state {
		pins = "gpio111", "gpio112", "gpio113", "gpio114";
		function = "cci_i2c";
		bias-pull-down;
		drive-strength = <2>;
	};

	/*
	 * CAMIF_MCLK1 -> the rear ultrawide. Vendor cam_sensor_mclk1_active:
	 * function "cam_mclk", bias-disable, drive-strength 2.
	 */
	cam_mclk1_active: cam-mclk1-active-state {
		pins = "gpio101";
		function = "cam_mclk";
		drive-strength = <2>;
		bias-disable;
	};

	/*
	 * UWCAM_RST_N, the ultrawide module's XCLR. Vendor
	 * cam_sensor_active_rst2: function "gpio", bias-disable, 2 mA.
	 */
	cam_uw_reset: cam-uw-reset-state {
		pins = "gpio106";
		function = "gpio";
		drive-strength = <2>;
		bias-disable;
	};
};

&soc {
	/*
	 * CCI1 (the camera i2c controller), hardware instance 1 at 0xac50000.
	 *
	 * NOTE the base address: SM8250 and SC8280XP put their two CCIs at
	 * 0xac4a000/0xac4b000, but SM8350 does NOT -- the vendor DT says
	 * 0xac4f000 (CCI0) and 0xac50000 (CCI1). Copying the sm8250 node
	 * wholesale would point at nothing.
	 *
	 * No driver change is needed: mainline i2c-qcom-cci has no
	 * qcom,sm8350-cci, but SM8350's CCI is register-compatible with the
	 * cci_v2 generation, so the sm8250 compatible serves as the fallback
	 * that actually matches (the same trick sc8280xp.dtsi uses with
	 * qcom,msm8996-cci). The driver takes its clocks with
	 * devm_clk_bulk_get_all(), so clock-names here are documentation only.
	 */
	cci1: cci@ac50000 {
		compatible = "qcom,sm8350-cci", "qcom,sm8250-cci";
		reg = <0 0x0ac50000 0 0x1000>;

		interrupts = <GIC_SPI 271 IRQ_TYPE_EDGE_RISING>;

		clocks = <&camcc CAM_CC_CAMNOC_AXI_CLK>,
			 <&camcc CAM_CC_SLOW_AHB_CLK_SRC>,
			 <&camcc CAM_CC_CPAS_AHB_CLK>,
			 <&camcc CAM_CC_CCI_1_CLK>;
		clock-names = "camnoc_axi",
			      "slow_ahb_src",
			      "cpas_ahb",
			      "cci";

		power-domains = <&camcc TITAN_TOP_GDSC>;

		pinctrl-names = "default", "sleep";
		pinctrl-0 = <&cci1_default>;
		pinctrl-1 = <&cci1_sleep>;

		#address-cells = <1>;
		#size-cells = <0>;

		status = "okay";

		/*
		 * Master 0 (TLMM 111/112) carries the ultrawide and its
		 * calibration EEPROM (vendor qcom,eeprom2, slave 0xa2 =
		 * 7-bit 0x51; no mainline driver for it, so it is not
		 * described here).
		 *
		 * 100 kHz deliberately: the vendor runs this bus at 1 MHz,
		 * but standard mode is the conservative choice for first
		 * contact and nothing here is throughput-bound. Raise it once
		 * the sensor is known to answer.
		 */
		cci1_i2c0: i2c-bus@0 {
			reg = <0>;
			clock-frequency = <100000>;
			#address-cells = <1>;
			#size-cells = <0>;

			/*
			 * The i2c address is the ONE fact the device tree
			 * cannot supply: the vendor's cam-sensor nodes carry
			 * no slave-addr, because Qualcomm's stack is told the
			 * address by userspace in the probe packet. 0x1a is
			 * the usual IMX258 address and what the only in-tree
			 * user (rk3399-pinephone-pro) uses; 0x10, 0x20 and
			 * 0x6c are the other strap options. If this does not
			 * probe, scan the bus -- CCI masters appear as normal
			 * Linux i2c adapters, so i2cdetect settles it.
			 */
			imx258: camera@1a {
				compatible = "sony,imx258";
				reg = <0x1a>;

				clocks = <&camcc CAM_CC_MCLK1_CLK>;
				assigned-clocks = <&camcc CAM_CC_MCLK1_CLK>;
				assigned-clock-rates = <19200000>;

				reset-gpios = <&tlmm 106 GPIO_ACTIVE_LOW>;

				pinctrl-names = "default";
				pinctrl-0 = <&cam_mclk1_active>, <&cam_uw_reset>;

				/*
				 * Vendor qcom,cam-sensor2 rgltr-min-voltage:
				 * 1.2 V vdig, 1.8 V vio, 2.7 V vana. The
				 * fourth rail it names, cam_v_custom1 (buck2,
				 * 1.3 V), has no consumer in imx258.c and is
				 * held always-on at the PMIC instead.
				 */
				vdig-supply = <&s2mpb02_main_l4>;
				vif-supply = <&s2mpb02_main_l6>;
				vana-supply = <&s2mpb02_main_l12>;

				/*
				 * 0 = front, 1 = back, 2 = external. This is
				 * a rear camera; with 0 here libcamera calls
				 * it "Internal front camera".
				 */
				orientation = <1>;
				rotation = <0>;

				port {
					imx258_ep: endpoint {
						remote-endpoint = <&csiphy4_ep>;
						/*
						 * Sensor side counts lanes from
						 * 1, the camss side from 0.
						 * 633.6 MHz is the 19.2 MHz
						 * clock's full-res link
						 * frequency (the 24 MHz part
						 * would be 636 MHz).
						 */
						data-lanes = <1 2 3 4>;
						link-frequencies =
							/bits/ 64 <633600000>;
					};
				};
			};
		};

		/* Master 1 (TLMM 113/114). Nothing described on it yet. */
		cci1_i2c1: i2c-bus@1 {
			reg = <1>;
			clock-frequency = <100000>;
			#address-cells = <1>;
			#size-cells = <0>;
		};
	};

	/*
	 * camss. Mainline has no qcom,sm8350-camss; the driver side is added by
	 * patches/0010 and camera-work/port-csiphy-sm8350.py.
	 *
	 * SM8350 is Titan 580, and 580 turns out to be register-identical to
	 * SM8250's Titan 480 everywhere camss touches: Qualcomm files both
	 * under vfe17x, cam_vfe580.h #includes cam_vfe480.h and reuses
	 * vfe480_top_common_reg / vfe480_bus_hw_info / vfe480_top_irq_reg_info
	 * verbatim, and "qcom,csid580" maps to cam_ife_csid480_hw_info. So the
	 * port reuses vfe_ops_480 + csid_ops_gen2 unchanged.
	 *
	 * What differs from SM8250 is the topology and the CSIPHY:
	 *   - 3 full IFEs + 2 IFE-lites (SM8250 has 2 + 2), hence 3 CSIDs + 2
	 *     lite CSIDs. CSID has no reg of its own on this generation: it
	 *     lives at vfe_base + 0x1200 (0xacb5200 - 0xacb4000 in the vendor
	 *     DT), which is why only csiphy/vfe appear in reg-names.
	 *   - CSIPHY is v1.2.3, where SM8250 is v1.2.1 -- a different vendor
	 *     register sequence, so lane_regs_sm8350 had to be generated.
	 *
	 * Addresses and interrupts are all from the vendor's
	 * lahaina-camera.dtsi, not inferred from sm8250.
	 */
	camss: isp@ac6a000 {
		compatible = "qcom,sm8350-camss";

		reg = <0 0x0ac6a000 0 0x2000>,
		      <0 0x0ac6c000 0 0x2000>,
		      <0 0x0ac6e000 0 0x2000>,
		      <0 0x0ac70000 0 0x2000>,
		      <0 0x0ac72000 0 0x2000>,
		      <0 0x0ac74000 0 0x2000>,
		      <0 0x0acb4000 0 0xd000>,
		      <0 0x0acc3000 0 0xd000>,
		      <0 0x0acef000 0 0xd000>,
		      <0 0x0acd9000 0 0x2200>,
		      <0 0x0acdb200 0 0x2200>;
		reg-names = "csiphy0",
			    "csiphy1",
			    "csiphy2",
			    "csiphy3",
			    "csiphy4",
			    "csiphy5",
			    "vfe0",
			    "vfe1",
			    "vfe2",
			    "vfe_lite0",
			    "vfe_lite1";

		interrupts = <GIC_SPI 477 IRQ_TYPE_EDGE_RISING>,
			     <GIC_SPI 478 IRQ_TYPE_EDGE_RISING>,
			     <GIC_SPI 479 IRQ_TYPE_EDGE_RISING>,
			     <GIC_SPI 448 IRQ_TYPE_EDGE_RISING>,
			     <GIC_SPI 122 IRQ_TYPE_EDGE_RISING>,
			     <GIC_SPI 89 IRQ_TYPE_EDGE_RISING>,
			     <GIC_SPI 464 IRQ_TYPE_EDGE_RISING>,
			     <GIC_SPI 466 IRQ_TYPE_EDGE_RISING>,
			     <GIC_SPI 640 IRQ_TYPE_EDGE_RISING>,
			     <GIC_SPI 468 IRQ_TYPE_EDGE_RISING>,
			     <GIC_SPI 359 IRQ_TYPE_EDGE_RISING>,
			     <GIC_SPI 465 IRQ_TYPE_EDGE_RISING>,
			     <GIC_SPI 467 IRQ_TYPE_EDGE_RISING>,
			     <GIC_SPI 641 IRQ_TYPE_EDGE_RISING>,
			     <GIC_SPI 469 IRQ_TYPE_EDGE_RISING>,
			     <GIC_SPI 360 IRQ_TYPE_EDGE_RISING>;
		interrupt-names = "csiphy0",
				  "csiphy1",
				  "csiphy2",
				  "csiphy3",
				  "csiphy4",
				  "csiphy5",
				  "csid0",
				  "csid1",
				  "csid2",
				  "csid3",
				  "csid4",
				  "vfe0",
				  "vfe1",
				  "vfe2",
				  "vfe_lite0",
				  "vfe_lite1";

		/*
		 * TITAN_TOP must come last: camss attaches the whole-block
		 * domain by index genpd_num - 1 when attach-by-name finds no
		 * power-domain-names (camss_configure_pd()).
		 */
		power-domains = <&camcc IFE_0_GDSC>,
				<&camcc IFE_1_GDSC>,
				<&camcc IFE_2_GDSC>,
				<&camcc TITAN_TOP_GDSC>;

		clocks = <&gcc GCC_CAMERA_HF_AXI_CLK>,
			 <&gcc GCC_CAMERA_SF_AXI_CLK>,
			 <&camcc CAM_CC_CAMNOC_AXI_CLK>,
			 <&camcc CAM_CC_CAMNOC_AXI_CLK_SRC>,
			 <&camcc CAM_CC_CPAS_AHB_CLK>,
			 <&camcc CAM_CC_SLOW_AHB_CLK_SRC>,
			 <&camcc CAM_CC_CSIPHY0_CLK>,
			 <&camcc CAM_CC_CSI0PHYTIMER_CLK>,
			 <&camcc CAM_CC_CSIPHY1_CLK>,
			 <&camcc CAM_CC_CSI1PHYTIMER_CLK>,
			 <&camcc CAM_CC_CSIPHY2_CLK>,
			 <&camcc CAM_CC_CSI2PHYTIMER_CLK>,
			 <&camcc CAM_CC_CSIPHY3_CLK>,
			 <&camcc CAM_CC_CSI3PHYTIMER_CLK>,
			 <&camcc CAM_CC_CSIPHY4_CLK>,
			 <&camcc CAM_CC_CSI4PHYTIMER_CLK>,
			 <&camcc CAM_CC_CSIPHY5_CLK>,
			 <&camcc CAM_CC_CSI5PHYTIMER_CLK>,
			 <&camcc CAM_CC_IFE_0_CLK>,
			 <&camcc CAM_CC_IFE_0_AHB_CLK>,
			 <&camcc CAM_CC_IFE_0_AREG_CLK>,
			 <&camcc CAM_CC_IFE_0_AXI_CLK>,
			 <&camcc CAM_CC_IFE_0_CSID_CLK>,
			 <&camcc CAM_CC_IFE_0_CPHY_RX_CLK>,
			 <&camcc CAM_CC_IFE_1_CLK>,
			 <&camcc CAM_CC_IFE_1_AHB_CLK>,
			 <&camcc CAM_CC_IFE_1_AREG_CLK>,
			 <&camcc CAM_CC_IFE_1_AXI_CLK>,
			 <&camcc CAM_CC_IFE_1_CSID_CLK>,
			 <&camcc CAM_CC_IFE_1_CPHY_RX_CLK>,
			 <&camcc CAM_CC_IFE_2_CLK>,
			 <&camcc CAM_CC_IFE_2_AHB_CLK>,
			 <&camcc CAM_CC_IFE_2_AREG_CLK>,
			 <&camcc CAM_CC_IFE_2_AXI_CLK>,
			 <&camcc CAM_CC_IFE_2_CSID_CLK>,
			 <&camcc CAM_CC_IFE_2_CPHY_RX_CLK>,
			 <&camcc CAM_CC_IFE_LITE_CLK>,
			 <&camcc CAM_CC_IFE_LITE_AHB_CLK>,
			 <&camcc CAM_CC_IFE_LITE_AXI_CLK>,
			 <&camcc CAM_CC_IFE_LITE_CSID_CLK>,
			 <&camcc CAM_CC_IFE_LITE_CPHY_RX_CLK>;
		clock-names = "cam_hf_axi",
			      "cam_sf_axi",
			      "camnoc_axi",
			      "camnoc_axi_src",
			      "cpas_ahb",
			      "slow_ahb_src",
			      "csiphy0",
			      "csiphy0_timer",
			      "csiphy1",
			      "csiphy1_timer",
			      "csiphy2",
			      "csiphy2_timer",
			      "csiphy3",
			      "csiphy3_timer",
			      "csiphy4",
			      "csiphy4_timer",
			      "csiphy5",
			      "csiphy5_timer",
			      "vfe0",
			      "vfe0_ahb",
			      "vfe0_areg",
			      "vfe0_axi",
			      "vfe0_csid",
			      "vfe0_cphy_rx",
			      "vfe1",
			      "vfe1_ahb",
			      "vfe1_areg",
			      "vfe1_axi",
			      "vfe1_csid",
			      "vfe1_cphy_rx",
			      "vfe2",
			      "vfe2_ahb",
			      "vfe2_areg",
			      "vfe2_axi",
			      "vfe2_csid",
			      "vfe2_cphy_rx",
			      "vfe_lite",
			      "vfe_lite_ahb",
			      "vfe_lite_axi",
			      "vfe_lite_csid",
			      "vfe_lite_cphy_rx";

		/*
		 * CSIPHY analog supplies. The vendor csiphy nodes name
		 * csi-vdd-1p2 = pm8350_l6 and csi-vdd-0p9 = pm8350_l5
		 * (1.2 V / 0.88 V), which are mainline's vdda-pll / vdda-phy.
		 * Both rails are already declared for other consumers.
		 */
		vdda-phy-supply = <&pm8350_l5>;
		vdda-pll-supply = <&pm8350_l6>;

		/*
		 * Stream IDs from the vendor's msm_cam_smmu_ife context bank.
		 * Mask 0x440, not sm8250's 0x400.
		 */
		iommus = <&apps_smmu 0x800 0x440>,
			 <&apps_smmu 0x840 0x440>,
			 <&apps_smmu 0xc00 0x440>,
			 <&apps_smmu 0xc40 0x440>;

		interconnects = <&gem_noc MASTER_APPSS_PROC 0 &config_noc SLAVE_CAMERA_CFG 0>,
				<&mmss_noc MASTER_CAMNOC_HF 0 &mc_virt SLAVE_EBI1 0>,
				<&mmss_noc MASTER_CAMNOC_SF 0 &mc_virt SLAVE_EBI1 0>,
				<&mmss_noc MASTER_CAMNOC_ICP 0 &mc_virt SLAVE_EBI1 0>;
		interconnect-names = "cam_ahb",
				     "cam_hf_0_mnoc",
				     "cam_sf_0_mnoc",
				     "cam_sf_icp_mnoc";

		status = "okay";

		/*
		 * Port index == CSIPHY index. Only CSIPHY4 is wired up so far;
		 * the ultrawide sits there per the vendor's
		 * qcom,cam-sensor2 csiphy-sd-index = <4>.
		 */
		ports {
			#address-cells = <1>;
			#size-cells = <0>;

			port@4 {
				reg = <4>;

				csiphy4_ep: endpoint {
					clock-lanes = <7>;
					data-lanes = <0 1 2 3>;
					remote-endpoint = <&imx258_ep>;
				};
			};
		};
	};
};

/*
 * TEMPORARY sensor power rig (2026-11-15). camera-work/sensor-rig/.
 *
 * Holds the rear ultrawide module powered, un-reset and clocked so the CCI
 * bus can be scanned for its i2c address -- the one fact the device tree
 * cannot supply, because Qualcomm's stack learns it from userspace and the
 * vendor's qcom,cam-sensor nodes carry no slave-addr.
 *
 * It coexists with the imx258 node above on purpose. If the address there is
 * wrong, imx258 fails its chip-ID read and devm releases the reset GPIO and
 * the rails, after which `insmod q2q-sensor-rig.ko` can claim them. Once the
 * address is right, imx258 keeps the GPIO and the rig simply fails to bind,
 * which is the correct outcome.
 *
 * Delete this node, and camera-work/sensor-rig/, once every sensor address is
 * known and recorded.
 */
/ {
	cam_uw_rig: cam-uw-rig {
		compatible = "q2q,sensor-rig";

		clocks = <&camcc CAM_CC_MCLK1_CLK>;
		clock-names = "mclk";

		power-domains = <&camcc TITAN_TOP_GDSC>;

		vdig-supply = <&s2mpb02_main_l4>;
		vif-supply = <&s2mpb02_main_l6>;
		vana-supply = <&s2mpb02_main_l12>;

		reset-gpios = <&tlmm 106 GPIO_ACTIVE_LOW>;

		pinctrl-names = "default";
		pinctrl-0 = <&cam_mclk1_active>, <&cam_uw_reset>;

		status = "okay";
	};
};
